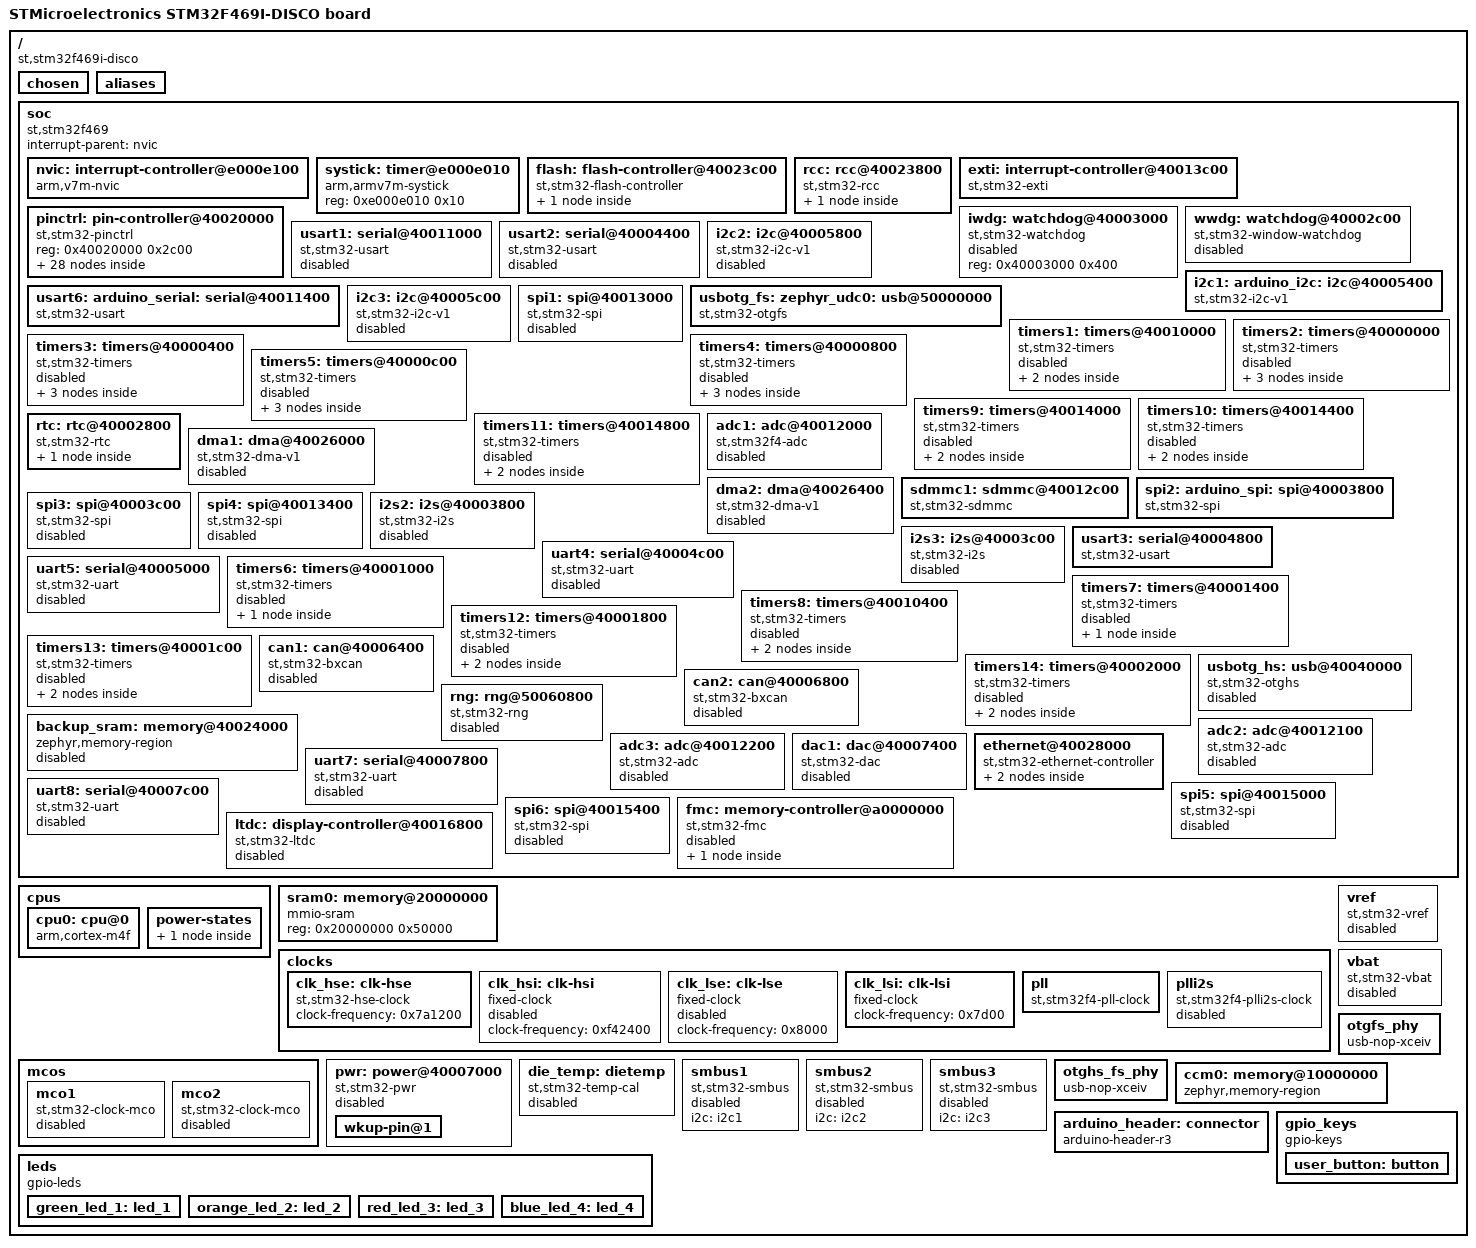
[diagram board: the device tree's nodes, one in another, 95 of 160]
/dts-v1/;

/* node '/' defined in zephyr\dts\common\skeleton.dtsi:9 */
/ {
	#address-cells = < 0x1 >;                            /* in zephyr\dts\common\skeleton.dtsi:10 */
	#size-cells = < 0x1 >;                               /* in zephyr\dts\common\skeleton.dtsi:11 */
	model = "STMicroelectronics STM32F469I-DISCO board"; /* in zephyr\boards\st\stm32f469i_disco\stm32f469i_disco.dts:14 */
	compatible = "st,stm32f469i-disco";                  /* in zephyr\boards\st\stm32f469i_disco\stm32f469i_disco.dts:15 */

	/* node '/chosen' defined in zephyr\dts\common\skeleton.dtsi:12 */
	chosen {
		zephyr,flash-controller = &flash;  /* in zephyr\dts\arm\st\f4\stm32f4.dtsi:26 */
		zephyr,cortex-m-idle-timer = &rtc; /* in zephyr\dts\arm\st\f4\stm32f4.dtsi:27 */
		zephyr,entropy = &rng;             /* in zephyr\dts\arm\st\f4\stm32f405.dtsi:12 */
		zephyr,console = &usart3;          /* in zephyr\boards\st\stm32f469i_disco\stm32f469i_disco.dts:18 */
		zephyr,shell-uart = &usart3;       /* in zephyr\boards\st\stm32f469i_disco\stm32f469i_disco.dts:19 */
		zephyr,sram = &sram0;              /* in zephyr\boards\st\stm32f469i_disco\stm32f469i_disco.dts:20 */
		zephyr,flash = &flash0;            /* in zephyr\boards\st\stm32f469i_disco\stm32f469i_disco.dts:21 */
		zephyr,ccm = &ccm0;                /* in zephyr\boards\st\stm32f469i_disco\stm32f469i_disco.dts:22 */
	};

	/* node '/aliases' defined in zephyr\dts\common\skeleton.dtsi:13 */
	aliases {
		led0 = &green_led_1;  /* in zephyr\boards\st\stm32f469i_disco\stm32f469i_disco.dts:60 */
		led1 = &orange_led_2; /* in zephyr\boards\st\stm32f469i_disco\stm32f469i_disco.dts:61 */
		led2 = &red_led_3;    /* in zephyr\boards\st\stm32f469i_disco\stm32f469i_disco.dts:62 */
		led3 = &blue_led_4;   /* in zephyr\boards\st\stm32f469i_disco\stm32f469i_disco.dts:63 */
		sw0 = &user_button;   /* in zephyr\boards\st\stm32f469i_disco\stm32f469i_disco.dts:64 */
	};

	/* node '/soc' defined in zephyr\dts\arm\armv7-m.dtsi:6 */
	soc {
		#address-cells = < 0x1 >;     /* in zephyr\dts\arm\armv7-m.dtsi:7 */
		#size-cells = < 0x1 >;        /* in zephyr\dts\arm\armv7-m.dtsi:8 */
		interrupt-parent = < &nvic >; /* in zephyr\dts\arm\armv7-m.dtsi:10 */
		ranges;                       /* in zephyr\dts\arm\armv7-m.dtsi:11 */
		compatible = "st,stm32f469",
		             "st,stm32f4",
		             "simple-bus";    /* in zephyr\dts\arm\st\f4\stm32f469.dtsi:11 */

		/* node '/soc/interrupt-controller@e000e100' defined in zephyr\dts\arm\armv7-m.dtsi:13 */
		nvic: interrupt-controller@e000e100 {
			#address-cells = < 0x1 >;            /* in zephyr\dts\arm\armv7-m.dtsi:14 */
			compatible = "arm,v7m-nvic";         /* in zephyr\dts\arm\armv7-m.dtsi:15 */
			reg = < 0xe000e100 0xc00 >;          /* in zephyr\dts\arm\armv7-m.dtsi:16 */
			interrupt-controller;                /* in zephyr\dts\arm\armv7-m.dtsi:17 */
			#interrupt-cells = < 0x2 >;          /* in zephyr\dts\arm\armv7-m.dtsi:18 */
			arm,num-irq-priority-bits = < 0x4 >; /* in zephyr\dts\arm\st\f4\stm32f4.dtsi:664 */
			phandle = < 0x1 >;                   /* in zephyr\dts\arm\armv7-m.dtsi:10 */
		};

		/* node '/soc/timer@e000e010' defined in zephyr\dts\arm\armv7-m.dtsi:21 */
		systick: timer@e000e010 {
			compatible = "arm,armv7m-systick"; /* in zephyr\dts\arm\armv7-m.dtsi:22 */
			reg = < 0xe000e010 0x10 >;         /* in zephyr\dts\arm\armv7-m.dtsi:23 */
		};

		/* node '/soc/flash-controller@40023c00' defined in zephyr\dts\arm\st\f4\stm32f4.dtsi:109 */
		flash: flash-controller@40023c00 {
			compatible = "st,stm32-flash-controller",
			             "st,stm32f4-flash-controller"; /* in zephyr\dts\arm\st\f4\stm32f4.dtsi:110 */
			reg = < 0x40023c00 0x400 >;                 /* in zephyr\dts\arm\st\f4\stm32f4.dtsi:111 */
			interrupts = < 0x4 0x0 >;                   /* in zephyr\dts\arm\st\f4\stm32f4.dtsi:112 */
			#address-cells = < 0x1 >;                   /* in zephyr\dts\arm\st\f4\stm32f4.dtsi:114 */
			#size-cells = < 0x1 >;                      /* in zephyr\dts\arm\st\f4\stm32f4.dtsi:115 */

			/* node '/soc/flash-controller@40023c00/flash@8000000' defined in zephyr\dts\arm\st\f4\stm32f4.dtsi:117 */
			flash0: flash@8000000 {
				compatible = "st,stm32f4-nv-flash",
				             "st,stm32-nv-flash",
				             "soc-nv-flash";        /* in zephyr\dts\arm\st\f4\stm32f4.dtsi:118 */
				write-block-size = < 0x1 >;         /* in zephyr\dts\arm\st\f4\stm32f4.dtsi:121 */
				max-erase-time = < 0xfa0 >;         /* in zephyr\dts\arm\st\f4\stm32f4.dtsi:123 */
				reg = < 0x8000000 0x200000 >;       /* in zephyr\dts\arm\st\f4\stm32f469Xi.dtsi:24 */
			};
		};

		/* node '/soc/rcc@40023800' defined in zephyr\dts\arm\st\f4\stm32f4.dtsi:127 */
		rcc: rcc@40023800 {
			compatible = "st,stm32-rcc";     /* in zephyr\dts\arm\st\f4\stm32f4.dtsi:128 */
			#clock-cells = < 0x2 >;          /* in zephyr\dts\arm\st\f4\stm32f4.dtsi:129 */
			reg = < 0x40023800 0x400 >;      /* in zephyr\dts\arm\st\f4\stm32f4.dtsi:130 */
			clocks = < &pll >;               /* in zephyr\boards\st\stm32f469i_disco\stm32f469i_disco.dts:87 */
			clock-frequency = < 0xa037a00 >; /* in zephyr\boards\st\stm32f469i_disco\stm32f469i_disco.dts:88 */
			ahb-prescaler = < 0x1 >;         /* in zephyr\boards\st\stm32f469i_disco\stm32f469i_disco.dts:89 */
			apb1-prescaler = < 0x4 >;        /* in zephyr\boards\st\stm32f469i_disco\stm32f469i_disco.dts:90 */
			apb2-prescaler = < 0x2 >;        /* in zephyr\boards\st\stm32f469i_disco\stm32f469i_disco.dts:91 */
			phandle = < 0x3 >;               /* in zephyr\dts\arm\st\f4\stm32f4.dtsi:144 */

			/* node '/soc/rcc@40023800/reset-controller' defined in zephyr\dts\arm\st\f4\stm32f4.dtsi:132 */
			rctl: reset-controller {
				compatible = "st,stm32-rcc-rctl"; /* in zephyr\dts\arm\st\f4\stm32f4.dtsi:133 */
				#reset-cells = < 0x1 >;           /* in zephyr\dts\arm\st\f4\stm32f4.dtsi:134 */
				phandle = < 0x4 >;                /* in zephyr\dts\arm\st\f4\stm32f4.dtsi:243 */
			};
		};

		/* node '/soc/interrupt-controller@40013c00' defined in zephyr\dts\arm\st\f4\stm32f4.dtsi:138 */
		exti: interrupt-controller@40013c00 {
			compatible = "st,stm32-exti";  /* in zephyr\dts\arm\st\f4\stm32f4.dtsi:139 */
			interrupt-controller;          /* in zephyr\dts\arm\st\f4\stm32f4.dtsi:140 */
			#interrupt-cells = < 0x1 >;    /* in zephyr\dts\arm\st\f4\stm32f4.dtsi:141 */
			#address-cells = < 0x1 >;      /* in zephyr\dts\arm\st\f4\stm32f4.dtsi:142 */
			reg = < 0x40013c00 0x400 >;    /* in zephyr\dts\arm\st\f4\stm32f4.dtsi:143 */
			clocks = < &rcc 0x44 0x4000 >; /* in zephyr\dts\arm\st\f4\stm32f4.dtsi:144 */
			num-lines = < 0x20 >;          /* in zephyr\dts\arm\st\f4\stm32f4.dtsi:145 */
			interrupts = < 0x6 0x0 >,
			             < 0x7 0x0 >,
			             < 0x8 0x0 >,
			             < 0x9 0x0 >,
			             < 0xa 0x0 >,
			             < 0x17 0x0 >,
			             < 0x28 0x0 >;     /* in zephyr\dts\arm\st\f4\stm32f4.dtsi:146 */
			interrupt-names = "line0",
			                  "line1",
			                  "line2",
			                  "line3",
			                  "line4",
			                  "line5-9",
			                  "line10-15"; /* in zephyr\dts\arm\st\f4\stm32f4.dtsi:148 */
			line-ranges = < 0x0 0x1 >,
			              < 0x1 0x1 >,
			              < 0x2 0x1 >,
			              < 0x3 0x1 >,
			              < 0x4 0x1 >,
			              < 0x5 0x5 >,
			              < 0xa 0x6 >;     /* in zephyr\dts\arm\st\f4\stm32f4.dtsi:150 */
		};

		/* node '/soc/pin-controller@40020000' defined in zephyr\dts\arm\st\f4\stm32f4.dtsi:154 */
		pinctrl: pin-controller@40020000 {
			compatible = "st,stm32-pinctrl"; /* in zephyr\dts\arm\st\f4\stm32f4.dtsi:155 */
			#address-cells = < 0x1 >;        /* in zephyr\dts\arm\st\f4\stm32f4.dtsi:156 */
			#size-cells = < 0x1 >;           /* in zephyr\dts\arm\st\f4\stm32f4.dtsi:157 */
			reg = < 0x40020000 0x2c00 >;     /* in zephyr\dts\arm\st\f4\stm32f427.dtsi:16 */

			/* node '/soc/pin-controller@40020000/gpio@40020000' defined in zephyr\dts\arm\st\f4\stm32f4.dtsi:160 */
			gpioa: gpio@40020000 {
				compatible = "st,stm32-gpio"; /* in zephyr\dts\arm\st\f4\stm32f4.dtsi:161 */
				gpio-controller;              /* in zephyr\dts\arm\st\f4\stm32f4.dtsi:162 */
				#gpio-cells = < 0x2 >;        /* in zephyr\dts\arm\st\f4\stm32f4.dtsi:163 */
				reg = < 0x40020000 0x400 >;   /* in zephyr\dts\arm\st\f4\stm32f4.dtsi:164 */
				clocks = < &rcc 0x30 0x1 >;   /* in zephyr\dts\arm\st\f4\stm32f4.dtsi:165 */
				phandle = < 0x1d >;           /* in zephyr\dts\arm\st\f4\stm32f4.dtsi:603 */
			};

			/* node '/soc/pin-controller@40020000/gpio@40020400' defined in zephyr\dts\arm\st\f4\stm32f4.dtsi:168 */
			gpiob: gpio@40020400 {
				compatible = "st,stm32-gpio"; /* in zephyr\dts\arm\st\f4\stm32f4.dtsi:169 */
				gpio-controller;              /* in zephyr\dts\arm\st\f4\stm32f4.dtsi:170 */
				#gpio-cells = < 0x2 >;        /* in zephyr\dts\arm\st\f4\stm32f4.dtsi:171 */
				reg = < 0x40020400 0x400 >;   /* in zephyr\dts\arm\st\f4\stm32f4.dtsi:172 */
				clocks = < &rcc 0x30 0x2 >;   /* in zephyr\dts\arm\st\f4\stm32f4.dtsi:173 */
				phandle = < 0x22 >;           /* in zephyr\boards\st\stm32f469i_disco\arduino_r3_connector.dtsi:13 */
			};

			/* node '/soc/pin-controller@40020000/gpio@40020800' defined in zephyr\dts\arm\st\f4\stm32f4.dtsi:176 */
			gpioc: gpio@40020800 {
				compatible = "st,stm32-gpio"; /* in zephyr\dts\arm\st\f4\stm32f4.dtsi:177 */
				gpio-controller;              /* in zephyr\dts\arm\st\f4\stm32f4.dtsi:178 */
				#gpio-cells = < 0x2 >;        /* in zephyr\dts\arm\st\f4\stm32f4.dtsi:179 */
				reg = < 0x40020800 0x400 >;   /* in zephyr\dts\arm\st\f4\stm32f4.dtsi:180 */
				clocks = < &rcc 0x30 0x4 >;   /* in zephyr\dts\arm\st\f4\stm32f4.dtsi:181 */
				phandle = < 0x23 >;           /* in zephyr\boards\st\stm32f469i_disco\arduino_r3_connector.dtsi:13 */
			};

			/* node '/soc/pin-controller@40020000/gpio@40020c00' defined in zephyr\dts\arm\st\f4\stm32f4.dtsi:184 */
			gpiod: gpio@40020c00 {
				compatible = "st,stm32-gpio"; /* in zephyr\dts\arm\st\f4\stm32f4.dtsi:185 */
				gpio-controller;              /* in zephyr\dts\arm\st\f4\stm32f4.dtsi:186 */
				#gpio-cells = < 0x2 >;        /* in zephyr\dts\arm\st\f4\stm32f4.dtsi:187 */
				reg = < 0x40020c00 0x400 >;   /* in zephyr\dts\arm\st\f4\stm32f4.dtsi:188 */
				clocks = < &rcc 0x30 0x8 >;   /* in zephyr\dts\arm\st\f4\stm32f4.dtsi:189 */
				phandle = < 0x24 >;           /* in zephyr\boards\st\stm32f469i_disco\arduino_r3_connector.dtsi:13 */
			};

			/* node '/soc/pin-controller@40020000/gpio@40021000' defined in zephyr\dts\arm\st\f4\stm32f4.dtsi:192 */
			gpioe: gpio@40021000 {
				compatible = "st,stm32-gpio"; /* in zephyr\dts\arm\st\f4\stm32f4.dtsi:193 */
				gpio-controller;              /* in zephyr\dts\arm\st\f4\stm32f4.dtsi:194 */
				#gpio-cells = < 0x2 >;        /* in zephyr\dts\arm\st\f4\stm32f4.dtsi:195 */
				reg = < 0x40021000 0x400 >;   /* in zephyr\dts\arm\st\f4\stm32f4.dtsi:196 */
				clocks = < &rcc 0x30 0x10 >;  /* in zephyr\dts\arm\st\f4\stm32f4.dtsi:197 */
			};

			/* node '/soc/pin-controller@40020000/gpio@40021400' defined in zephyr\dts\arm\st\f4\stm32f4.dtsi:200 */
			gpiof: gpio@40021400 {
				compatible = "st,stm32-gpio"; /* in zephyr\dts\arm\st\f4\stm32f405.dtsi:22 */
				gpio-controller;              /* in zephyr\dts\arm\st\f4\stm32f405.dtsi:23 */
				#gpio-cells = < 0x2 >;        /* in zephyr\dts\arm\st\f4\stm32f405.dtsi:24 */
				reg = < 0x40021400 0x400 >;   /* in zephyr\dts\arm\st\f4\stm32f405.dtsi:25 */
				clocks = < &rcc 0x30 0x20 >;  /* in zephyr\dts\arm\st\f4\stm32f405.dtsi:26 */
			};

			/* node '/soc/pin-controller@40020000/gpio@40021800' defined in zephyr\dts\arm\st\f4\stm32f4.dtsi:208 */
			gpiog: gpio@40021800 {
				compatible = "st,stm32-gpio"; /* in zephyr\dts\arm\st\f4\stm32f405.dtsi:30 */
				gpio-controller;              /* in zephyr\dts\arm\st\f4\stm32f405.dtsi:31 */
				#gpio-cells = < 0x2 >;        /* in zephyr\dts\arm\st\f4\stm32f405.dtsi:32 */
				reg = < 0x40021800 0x400 >;   /* in zephyr\dts\arm\st\f4\stm32f405.dtsi:33 */
				clocks = < &rcc 0x30 0x40 >;  /* in zephyr\dts\arm\st\f4\stm32f405.dtsi:34 */
				phandle = < 0x12 >;           /* in zephyr\boards\st\stm32f469i_disco\stm32f469i_disco.dts:144 */
			};

			/* node '/soc/pin-controller@40020000/gpio@40021c00' defined in zephyr\dts\arm\st\f4\stm32f4.dtsi:216 */
			gpioh: gpio@40021c00 {
				compatible = "st,stm32-gpio"; /* in zephyr\dts\arm\st\f4\stm32f4.dtsi:217 */
				gpio-controller;              /* in zephyr\dts\arm\st\f4\stm32f4.dtsi:218 */
				#gpio-cells = < 0x2 >;        /* in zephyr\dts\arm\st\f4\stm32f4.dtsi:219 */
				reg = < 0x40021c00 0x400 >;   /* in zephyr\dts\arm\st\f4\stm32f4.dtsi:220 */
				clocks = < &rcc 0x30 0x80 >;  /* in zephyr\dts\arm\st\f4\stm32f4.dtsi:221 */
				phandle = < 0x16 >;           /* in zephyr\boards\st\stm32f469i_disco\stm32f469i_disco.dts:117 */
			};

			/* node '/soc/pin-controller@40020000/gpio@40022000' defined in zephyr\dts\arm\st\f4\stm32f405.dtsi:37 */
			gpioi: gpio@40022000 {
				compatible = "st,stm32-gpio"; /* in zephyr\dts\arm\st\f4\stm32f405.dtsi:38 */
				gpio-controller;              /* in zephyr\dts\arm\st\f4\stm32f405.dtsi:39 */
				#gpio-cells = < 0x2 >;        /* in zephyr\dts\arm\st\f4\stm32f405.dtsi:40 */
				reg = < 0x40022000 0x400 >;   /* in zephyr\dts\arm\st\f4\stm32f405.dtsi:41 */
				clocks = < &rcc 0x30 0x100 >; /* in zephyr\dts\arm\st\f4\stm32f405.dtsi:42 */
			};

			/* node '/soc/pin-controller@40020000/gpio@40022400' defined in zephyr\dts\arm\st\f4\stm32f427.dtsi:18 */
			gpioj: gpio@40022400 {
				compatible = "st,stm32-gpio"; /* in zephyr\dts\arm\st\f4\stm32f427.dtsi:19 */
				gpio-controller;              /* in zephyr\dts\arm\st\f4\stm32f427.dtsi:20 */
				#gpio-cells = < 0x2 >;        /* in zephyr\dts\arm\st\f4\stm32f427.dtsi:21 */
				reg = < 0x40022400 0x400 >;   /* in zephyr\dts\arm\st\f4\stm32f427.dtsi:22 */
				clocks = < &rcc 0x30 0x200 >; /* in zephyr\dts\arm\st\f4\stm32f427.dtsi:23 */
			};

			/* node '/soc/pin-controller@40020000/gpio@40022800' defined in zephyr\dts\arm\st\f4\stm32f427.dtsi:26 */
			gpiok: gpio@40022800 {
				compatible = "st,stm32-gpio"; /* in zephyr\dts\arm\st\f4\stm32f427.dtsi:27 */
				gpio-controller;              /* in zephyr\dts\arm\st\f4\stm32f427.dtsi:28 */
				#gpio-cells = < 0x2 >;        /* in zephyr\dts\arm\st\f4\stm32f427.dtsi:29 */
				reg = < 0x40022800 0x400 >;   /* in zephyr\dts\arm\st\f4\stm32f427.dtsi:30 */
				clocks = < &rcc 0x30 0x400 >; /* in zephyr\dts\arm\st\f4\stm32f427.dtsi:31 */
				phandle = < 0x25 >;           /* in zephyr\boards\st\stm32f469i_disco\stm32f469i_disco.dts:44 */
			};

			/* node '/soc/pin-controller@40020000/i2c1_scl_pb8' defined in modules\hal\stm32\dts\st\f4\stm32f469nihx-pinctrl.dtsi:1856 */
			i2c1_scl_pb8: i2c1_scl_pb8 {
				pinmux = < 0x304 >; /* in modules\hal\stm32\dts\st\f4\stm32f469nihx-pinctrl.dtsi:1857 */
				bias-pull-up;       /* in modules\hal\stm32\dts\st\f4\stm32f469nihx-pinctrl.dtsi:1858 */
				drive-open-drain;   /* in modules\hal\stm32\dts\st\f4\stm32f469nihx-pinctrl.dtsi:1859 */
				phandle = < 0x7 >;  /* in zephyr\boards\st\stm32f469i_disco\stm32f469i_disco.dts:109 */
			};

			/* node '/soc/pin-controller@40020000/i2c1_sda_pb9' defined in modules\hal\stm32\dts\st\f4\stm32f469nihx-pinctrl.dtsi:1900 */
			i2c1_sda_pb9: i2c1_sda_pb9 {
				pinmux = < 0x324 >; /* in modules\hal\stm32\dts\st\f4\stm32f469nihx-pinctrl.dtsi:1901 */
				bias-pull-up;       /* in modules\hal\stm32\dts\st\f4\stm32f469nihx-pinctrl.dtsi:1902 */
				drive-open-drain;   /* in modules\hal\stm32\dts\st\f4\stm32f469nihx-pinctrl.dtsi:1903 */
				phandle = < 0x8 >;  /* in zephyr\boards\st\stm32f469i_disco\stm32f469i_disco.dts:109 */
			};

			/* node '/soc/pin-controller@40020000/sdio_d0_pc8' defined in modules\hal\stm32\dts\st\f4\stm32f469nihx-pinctrl.dtsi:2663 */
			sdio_d0_pc8: sdio_d0_pc8 {
				pinmux = < 0x50c >;            /* in modules\hal\stm32\dts\st\f4\stm32f469nihx-pinctrl.dtsi:2664 */
				bias-pull-up;                  /* in modules\hal\stm32\dts\st\f4\stm32f469nihx-pinctrl.dtsi:2665 */
				slew-rate = "very-high-speed"; /* in modules\hal\stm32\dts\st\f4\stm32f469nihx-pinctrl.dtsi:2666 */
				phandle = < 0xc >;             /* in zephyr\boards\st\stm32f469i_disco\stm32f469i_disco.dts:137 */
			};

			/* node '/soc/pin-controller@40020000/sdio_d1_pc9' defined in modules\hal\stm32\dts\st\f4\stm32f469nihx-pinctrl.dtsi:2669 */
			sdio_d1_pc9: sdio_d1_pc9 {
				pinmux = < 0x52c >;            /* in modules\hal\stm32\dts\st\f4\stm32f469nihx-pinctrl.dtsi:2670 */
				bias-pull-up;                  /* in modules\hal\stm32\dts\st\f4\stm32f469nihx-pinctrl.dtsi:2671 */
				slew-rate = "very-high-speed"; /* in modules\hal\stm32\dts\st\f4\stm32f469nihx-pinctrl.dtsi:2672 */
				phandle = < 0xd >;             /* in zephyr\boards\st\stm32f469i_disco\stm32f469i_disco.dts:137 */
			};

			/* node '/soc/pin-controller@40020000/sdio_d2_pc10' defined in modules\hal\stm32\dts\st\f4\stm32f469nihx-pinctrl.dtsi:2675 */
			sdio_d2_pc10: sdio_d2_pc10 {
				pinmux = < 0x54c >;            /* in modules\hal\stm32\dts\st\f4\stm32f469nihx-pinctrl.dtsi:2676 */
				bias-pull-up;                  /* in modules\hal\stm32\dts\st\f4\stm32f469nihx-pinctrl.dtsi:2677 */
				slew-rate = "very-high-speed"; /* in modules\hal\stm32\dts\st\f4\stm32f469nihx-pinctrl.dtsi:2678 */
				phandle = < 0xe >;             /* in zephyr\boards\st\stm32f469i_disco\stm32f469i_disco.dts:137 */
			};

			/* node '/soc/pin-controller@40020000/sdio_d3_pc11' defined in modules\hal\stm32\dts\st\f4\stm32f469nihx-pinctrl.dtsi:2681 */
			sdio_d3_pc11: sdio_d3_pc11 {
				pinmux = < 0x56c >;            /* in modules\hal\stm32\dts\st\f4\stm32f469nihx-pinctrl.dtsi:2682 */
				bias-pull-up;                  /* in modules\hal\stm32\dts\st\f4\stm32f469nihx-pinctrl.dtsi:2683 */
				slew-rate = "very-high-speed"; /* in modules\hal\stm32\dts\st\f4\stm32f469nihx-pinctrl.dtsi:2684 */
				phandle = < 0xf >;             /* in zephyr\boards\st\stm32f469i_disco\stm32f469i_disco.dts:137 */
			};

			/* node '/soc/pin-controller@40020000/sdio_ck_pc12' defined in modules\hal\stm32\dts\st\f4\stm32f469nihx-pinctrl.dtsi:2687 */
			sdio_ck_pc12: sdio_ck_pc12 {
				pinmux = < 0x58c >;            /* in modules\hal\stm32\dts\st\f4\stm32f469nihx-pinctrl.dtsi:2688 */
				bias-pull-up;                  /* in modules\hal\stm32\dts\st\f4\stm32f469nihx-pinctrl.dtsi:2689 */
				slew-rate = "very-high-speed"; /* in modules\hal\stm32\dts\st\f4\stm32f469nihx-pinctrl.dtsi:2690 */
				phandle = < 0x10 >;            /* in zephyr\boards\st\stm32f469i_disco\stm32f469i_disco.dts:137 */
			};

			/* node '/soc/pin-controller@40020000/sdio_cmd_pd2' defined in modules\hal\stm32\dts\st\f4\stm32f469nihx-pinctrl.dtsi:2693 */
			sdio_cmd_pd2: sdio_cmd_pd2 {
				pinmux = < 0x64c >;            /* in modules\hal\stm32\dts\st\f4\stm32f469nihx-pinctrl.dtsi:2694 */
				bias-pull-up;                  /* in modules\hal\stm32\dts\st\f4\stm32f469nihx-pinctrl.dtsi:2695 */
				slew-rate = "very-high-speed"; /* in modules\hal\stm32\dts\st\f4\stm32f469nihx-pinctrl.dtsi:2696 */
				phandle = < 0x11 >;            /* in zephyr\boards\st\stm32f469i_disco\stm32f469i_disco.dts:137 */
			};

			/* node '/soc/pin-controller@40020000/spi2_miso_pb14' defined in modules\hal\stm32\dts\st\f4\stm32f469nihx-pinctrl.dtsi:2711 */
			spi2_miso_pb14: spi2_miso_pb14 {
				pinmux = < 0x3c5 >; /* in modules\hal\stm32\dts\st\f4\stm32f469nihx-pinctrl.dtsi:2712 */
				bias-pull-down;     /* in modules\hal\stm32\dts\st\f4\stm32f469nihx-pinctrl.dtsi:2713 */
				phandle = < 0x14 >; /* in zephyr\boards\st\stm32f469i_disco\stm32f469i_disco.dts:115 */
			};

			/* node '/soc/pin-controller@40020000/spi2_mosi_pb15' defined in modules\hal\stm32\dts\st\f4\stm32f469nihx-pinctrl.dtsi:2773 */
			spi2_mosi_pb15: spi2_mosi_pb15 {
				pinmux = < 0x3e5 >; /* in modules\hal\stm32\dts\st\f4\stm32f469nihx-pinctrl.dtsi:2774 */
				bias-pull-down;     /* in modules\hal\stm32\dts\st\f4\stm32f469nihx-pinctrl.dtsi:2775 */
				phandle = < 0x15 >; /* in zephyr\boards\st\stm32f469i_disco\stm32f469i_disco.dts:115 */
			};

			/* node '/soc/pin-controller@40020000/spi2_sck_pd3' defined in modules\hal\stm32\dts\st\f4\stm32f469nihx-pinctrl.dtsi:2927 */
			spi2_sck_pd3: spi2_sck_pd3 {
				pinmux = < 0x665 >;            /* in modules\hal\stm32\dts\st\f4\stm32f469nihx-pinctrl.dtsi:2928 */
				bias-pull-down;                /* in modules\hal\stm32\dts\st\f4\stm32f469nihx-pinctrl.dtsi:2929 */
				slew-rate = "very-high-speed"; /* in modules\hal\stm32\dts\st\f4\stm32f469nihx-pinctrl.dtsi:2930 */
				phandle = < 0x13 >;            /* in zephyr\boards\st\stm32f469i_disco\stm32f469i_disco.dts:115 */
			};

			/* node '/soc/pin-controller@40020000/usart3_rx_pb11' defined in modules\hal\stm32\dts\st\f4\stm32f469nihx-pinctrl.dtsi:3437 */
			usart3_rx_pb11: usart3_rx_pb11 {
				pinmux = < 0x367 >; /* in modules\hal\stm32\dts\st\f4\stm32f469nihx-pinctrl.dtsi:3438 */
				phandle = < 0x19 >; /* in zephyr\boards\st\stm32f469i_disco\stm32f469i_disco.dts:95 */
			};

			/* node '/soc/pin-controller@40020000/usart6_rx_pg9' defined in modules\hal\stm32\dts\st\f4\stm32f469nihx-pinctrl.dtsi:3465 */
			usart6_rx_pg9: usart6_rx_pg9 {
				pinmux = < 0xd28 >; /* in modules\hal\stm32\dts\st\f4\stm32f469nihx-pinctrl.dtsi:3466 */
				phandle = < 0x6 >;  /* in zephyr\boards\st\stm32f469i_disco\stm32f469i_disco.dts:102 */
			};

			/* node '/soc/pin-controller@40020000/usart3_tx_pb10' defined in modules\hal\stm32\dts\st\f4\stm32f469nihx-pinctrl.dtsi:3503 */
			usart3_tx_pb10: usart3_tx_pb10 {
				pinmux = < 0x347 >; /* in modules\hal\stm32\dts\st\f4\stm32f469nihx-pinctrl.dtsi:3504 */
				bias-pull-up;       /* in modules\hal\stm32\dts\st\f4\stm32f469nihx-pinctrl.dtsi:3505 */
				phandle = < 0x18 >; /* in zephyr\boards\st\stm32f469i_disco\stm32f469i_disco.dts:95 */
			};

			/* node '/soc/pin-controller@40020000/usart6_tx_pg14' defined in modules\hal\stm32\dts\st\f4\stm32f469nihx-pinctrl.dtsi:3538 */
			usart6_tx_pg14: usart6_tx_pg14 {
				pinmux = < 0xdc8 >; /* in modules\hal\stm32\dts\st\f4\stm32f469nihx-pinctrl.dtsi:3539 */
				bias-pull-up;       /* in modules\hal\stm32\dts\st\f4\stm32f469nihx-pinctrl.dtsi:3540 */
				phandle = < 0x5 >;  /* in zephyr\boards\st\stm32f469i_disco\stm32f469i_disco.dts:102 */
			};

			/* node '/soc/pin-controller@40020000/usb_otg_fs_dm_pa11' defined in modules\hal\stm32\dts\st\f4\stm32f469nihx-pinctrl.dtsi:3572 */
			usb_otg_fs_dm_pa11: usb_otg_fs_dm_pa11 {
				pinmux = < 0x16a >; /* in modules\hal\stm32\dts\st\f4\stm32f469nihx-pinctrl.dtsi:3573 */
				phandle = < 0xa >;  /* in zephyr\boards\st\stm32f469i_disco\stm32f469i_disco.dts:122 */
			};

			/* node '/soc/pin-controller@40020000/usb_otg_fs_dp_pa12' defined in modules\hal\stm32\dts\st\f4\stm32f469nihx-pinctrl.dtsi:3576 */
			usb_otg_fs_dp_pa12: usb_otg_fs_dp_pa12 {
				pinmux = < 0x18a >; /* in modules\hal\stm32\dts\st\f4\stm32f469nihx-pinctrl.dtsi:3577 */
				phandle = < 0xb >;  /* in zephyr\boards\st\stm32f469i_disco\stm32f469i_disco.dts:122 */
			};
		};

		/* node '/soc/watchdog@40003000' defined in zephyr\dts\arm\st\f4\stm32f4.dtsi:225 */
		iwdg: watchdog@40003000 {
			compatible = "st,stm32-watchdog"; /* in zephyr\dts\arm\st\f4\stm32f4.dtsi:226 */
			reg = < 0x40003000 0x400 >;       /* in zephyr\dts\arm\st\f4\stm32f4.dtsi:227 */
			status = "disabled";              /* in zephyr\dts\arm\st\f4\stm32f4.dtsi:228 */
		};

		/* node '/soc/watchdog@40002c00' defined in zephyr\dts\arm\st\f4\stm32f4.dtsi:231 */
		wwdg: watchdog@40002c00 {
			compatible = "st,stm32-window-watchdog"; /* in zephyr\dts\arm\st\f4\stm32f4.dtsi:232 */
			reg = < 0x40002c00 0x400 >;              /* in zephyr\dts\arm\st\f4\stm32f4.dtsi:233 */
			clocks = < &rcc 0x40 0x800 >;            /* in zephyr\dts\arm\st\f4\stm32f4.dtsi:234 */
			interrupts = < 0x0 0x7 >;                /* in zephyr\dts\arm\st\f4\stm32f4.dtsi:235 */
			status = "disabled";                     /* in zephyr\dts\arm\st\f4\stm32f4.dtsi:236 */
		};

		/* node '/soc/serial@40011000' defined in zephyr\dts\arm\st\f4\stm32f4.dtsi:239 */
		usart1: serial@40011000 {
			compatible = "st,stm32-usart",
			             "st,stm32-uart";  /* in zephyr\dts\arm\st\f4\stm32f4.dtsi:240 */
			reg = < 0x40011000 0x400 >;    /* in zephyr\dts\arm\st\f4\stm32f4.dtsi:241 */
			clocks = < &rcc 0x44 0x10 >;   /* in zephyr\dts\arm\st\f4\stm32f4.dtsi:242 */
			resets = < &rctl 0x484 >;      /* in zephyr\dts\arm\st\f4\stm32f4.dtsi:243 */
			interrupts = < 0x25 0x0 >;     /* in zephyr\dts\arm\st\f4\stm32f4.dtsi:244 */
			status = "disabled";           /* in zephyr\dts\arm\st\f4\stm32f4.dtsi:245 */
		};

		/* node '/soc/serial@40004400' defined in zephyr\dts\arm\st\f4\stm32f4.dtsi:248 */
		usart2: serial@40004400 {
			compatible = "st,stm32-usart",
			             "st,stm32-uart";   /* in zephyr\dts\arm\st\f4\stm32f4.dtsi:249 */
			reg = < 0x40004400 0x400 >;     /* in zephyr\dts\arm\st\f4\stm32f4.dtsi:250 */
			clocks = < &rcc 0x40 0x20000 >; /* in zephyr\dts\arm\st\f4\stm32f4.dtsi:251 */
			resets = < &rctl 0x411 >;       /* in zephyr\dts\arm\st\f4\stm32f4.dtsi:252 */
			interrupts = < 0x26 0x0 >;      /* in zephyr\dts\arm\st\f4\stm32f4.dtsi:253 */
			status = "disabled";            /* in zephyr\dts\arm\st\f4\stm32f4.dtsi:254 */
		};

		/* node '/soc/serial@40011400' defined in zephyr\dts\arm\st\f4\stm32f4.dtsi:257 */
		usart6: arduino_serial: serial@40011400 {
			compatible = "st,stm32-usart",
			             "st,stm32-uart";                   /* in zephyr\dts\arm\st\f4\stm32f4.dtsi:258 */
			reg = < 0x40011400 0x400 >;                     /* in zephyr\dts\arm\st\f4\stm32f4.dtsi:259 */
			clocks = < &rcc 0x44 0x20 >;                    /* in zephyr\dts\arm\st\f4\stm32f4.dtsi:260 */
			resets = < &rctl 0x485 >;                       /* in zephyr\dts\arm\st\f4\stm32f4.dtsi:261 */
			interrupts = < 0x47 0x0 >;                      /* in zephyr\dts\arm\st\f4\stm32f4.dtsi:262 */
			pinctrl-0 = < &usart6_tx_pg14 &usart6_rx_pg9 >; /* in zephyr\boards\st\stm32f469i_disco\stm32f469i_disco.dts:102 */
			pinctrl-names = "default";                      /* in zephyr\boards\st\stm32f469i_disco\stm32f469i_disco.dts:103 */
			current-speed = < 0x1c200 >;                    /* in zephyr\boards\st\stm32f469i_disco\stm32f469i_disco.dts:104 */
			status = "okay";                                /* in zephyr\boards\st\stm32f469i_disco\stm32f469i_disco.dts:105 */
		};

		/* node '/soc/i2c@40005400' defined in zephyr\dts\arm\st\f4\stm32f4.dtsi:266 */
		i2c1: arduino_i2c: i2c@40005400 {
			compatible = "st,stm32-i2c-v1";              /* in zephyr\dts\arm\st\f4\stm32f4.dtsi:267 */
			clock-frequency = < 0x186a0 >;               /* in zephyr\dts\arm\st\f4\stm32f4.dtsi:268 */
			#address-cells = < 0x1 >;                    /* in zephyr\dts\arm\st\f4\stm32f4.dtsi:269 */
			#size-cells = < 0x0 >;                       /* in zephyr\dts\arm\st\f4\stm32f4.dtsi:270 */
			reg = < 0x40005400 0x400 >;                  /* in zephyr\dts\arm\st\f4\stm32f4.dtsi:271 */
			clocks = < &rcc 0x40 0x200000 >;             /* in zephyr\dts\arm\st\f4\stm32f4.dtsi:272 */
			interrupts = < 0x1f 0x0 >,
			             < 0x20 0x0 >;                   /* in zephyr\dts\arm\st\f4\stm32f4.dtsi:273 */
			interrupt-names = "event",
			                  "error";                   /* in zephyr\dts\arm\st\f4\stm32f4.dtsi:274 */
			pinctrl-0 = < &i2c1_scl_pb8 &i2c1_sda_pb9 >; /* in zephyr\boards\st\stm32f469i_disco\stm32f469i_disco.dts:109 */
			pinctrl-names = "default";                   /* in zephyr\boards\st\stm32f469i_disco\stm32f469i_disco.dts:110 */
			status = "okay";                             /* in zephyr\boards\st\stm32f469i_disco\stm32f469i_disco.dts:111 */
			phandle = < 0x1f >;                          /* in zephyr\dts\arm\st\f4\stm32f4.dtsi:642 */
		};

		/* node '/soc/i2c@40005800' defined in zephyr\dts\arm\st\f4\stm32f4.dtsi:278 */
		i2c2: i2c@40005800 {
			compatible = "st,stm32-i2c-v1";  /* in zephyr\dts\arm\st\f4\stm32f4.dtsi:279 */
			clock-frequency = < 0x186a0 >;   /* in zephyr\dts\arm\st\f4\stm32f4.dtsi:280 */
			#address-cells = < 0x1 >;        /* in zephyr\dts\arm\st\f4\stm32f4.dtsi:281 */
			#size-cells = < 0x0 >;           /* in zephyr\dts\arm\st\f4\stm32f4.dtsi:282 */
			reg = < 0x40005800 0x400 >;      /* in zephyr\dts\arm\st\f4\stm32f4.dtsi:283 */
			clocks = < &rcc 0x40 0x400000 >; /* in zephyr\dts\arm\st\f4\stm32f4.dtsi:284 */
			interrupts = < 0x21 0x0 >,
			             < 0x22 0x0 >;       /* in zephyr\dts\arm\st\f4\stm32f4.dtsi:285 */
			interrupt-names = "event",
			                  "error";       /* in zephyr\dts\arm\st\f4\stm32f4.dtsi:286 */
			status = "disabled";             /* in zephyr\dts\arm\st\f4\stm32f4.dtsi:287 */
			phandle = < 0x20 >;              /* in zephyr\dts\arm\st\f4\stm32f4.dtsi:650 */
		};

		/* node '/soc/i2c@40005c00' defined in zephyr\dts\arm\st\f4\stm32f4.dtsi:290 */
		i2c3: i2c@40005c00 {
			compatible = "st,stm32-i2c-v1";  /* in zephyr\dts\arm\st\f4\stm32f4.dtsi:291 */
			clock-frequency = < 0x186a0 >;   /* in zephyr\dts\arm\st\f4\stm32f4.dtsi:292 */
			#address-cells = < 0x1 >;        /* in zephyr\dts\arm\st\f4\stm32f4.dtsi:293 */
			#size-cells = < 0x0 >;           /* in zephyr\dts\arm\st\f4\stm32f4.dtsi:294 */
			reg = < 0x40005c00 0x400 >;      /* in zephyr\dts\arm\st\f4\stm32f4.dtsi:295 */
			clocks = < &rcc 0x40 0x800000 >; /* in zephyr\dts\arm\st\f4\stm32f4.dtsi:296 */
			interrupts = < 0x48 0x0 >,
			             < 0x49 0x0 >;       /* in zephyr\dts\arm\st\f4\stm32f4.dtsi:297 */
			interrupt-names = "event",
			                  "error";       /* in zephyr\dts\arm\st\f4\stm32f4.dtsi:298 */
			status = "disabled";             /* in zephyr\dts\arm\st\f4\stm32f4.dtsi:299 */
			phandle = < 0x21 >;              /* in zephyr\dts\arm\st\f4\stm32f4.dtsi:658 */
		};

		/* node '/soc/spi@40013000' defined in zephyr\dts\arm\st\f4\stm32f4.dtsi:302 */
		spi1: spi@40013000 {
			compatible = "st,stm32-spi";   /* in zephyr\dts\arm\st\f4\stm32f4.dtsi:303 */
			#address-cells = < 0x1 >;      /* in zephyr\dts\arm\st\f4\stm32f4.dtsi:304 */
			#size-cells = < 0x0 >;         /* in zephyr\dts\arm\st\f4\stm32f4.dtsi:305 */
			reg = < 0x40013000 0x400 >;    /* in zephyr\dts\arm\st\f4\stm32f4.dtsi:306 */
			clocks = < &rcc 0x44 0x1000 >; /* in zephyr\dts\arm\st\f4\stm32f4.dtsi:307 */
			interrupts = < 0x23 0x5 >;     /* in zephyr\dts\arm\st\f4\stm32f4.dtsi:308 */
			status = "disabled";           /* in zephyr\dts\arm\st\f4\stm32f4.dtsi:309 */
		};

		/* node '/soc/usb@50000000' defined in zephyr\dts\arm\st\f4\stm32f4.dtsi:312 */
		usbotg_fs: zephyr_udc0: usb@50000000 {
			compatible = "st,stm32-otgfs";                           /* in zephyr\dts\arm\st\f4\stm32f4.dtsi:313 */
			reg = < 0x50000000 0x40000 >;                            /* in zephyr\dts\arm\st\f4\stm32f4.dtsi:314 */
			interrupts = < 0x43 0x0 >;                               /* in zephyr\dts\arm\st\f4\stm32f4.dtsi:315 */
			interrupt-names = "otgfs";                               /* in zephyr\dts\arm\st\f4\stm32f4.dtsi:316 */
			ram-size = < 0x500 >;                                    /* in zephyr\dts\arm\st\f4\stm32f4.dtsi:318 */
			maximum-speed = "full-speed";                            /* in zephyr\dts\arm\st\f4\stm32f4.dtsi:319 */
			phys = < &otgfs_phy >;                                   /* in zephyr\dts\arm\st\f4\stm32f4.dtsi:320 */
			num-bidir-endpoints = < 0x6 >;                           /* in zephyr\dts\arm\st\f4\stm32f469.dtsi:19 */
			clocks = < &rcc 0x34 0x80 >,
			         < &rcc 0x7 0x5b008c >;                          /* in zephyr\dts\arm\st\f4\stm32f469.dtsi:20 */
			pinctrl-0 = < &usb_otg_fs_dm_pa11 &usb_otg_fs_dp_pa12 >; /* in zephyr\boards\st\stm32f469i_disco\stm32f469i_disco.dts:122 */
			pinctrl-names = "default";                               /* in zephyr\boards\st\stm32f469i_disco\stm32f469i_disco.dts:123 */
			status = "okay";                                         /* in zephyr\boards\st\stm32f469i_disco\stm32f469i_disco.dts:124 */
		};

		/* node '/soc/timers@40010000' defined in zephyr\dts\arm\st\f4\stm32f4.dtsi:326 */
		timers1: timers@40010000 {
			compatible = "st,stm32-timers"; /* in zephyr\dts\arm\st\f4\stm32f4.dtsi:327 */
			reg = < 0x40010000 0x400 >;     /* in zephyr\dts\arm\st\f4\stm32f4.dtsi:328 */
			clocks = < &rcc 0x44 0x1 >;     /* in zephyr\dts\arm\st\f4\stm32f4.dtsi:329 */
			resets = < &rctl 0x480 >;       /* in zephyr\dts\arm\st\f4\stm32f4.dtsi:330 */
			interrupts = < 0x18 0x0 >,
			             < 0x19 0x0 >,
			             < 0x1a 0x0 >,
			             < 0x1b 0x0 >;      /* in zephyr\dts\arm\st\f4\stm32f4.dtsi:331 */
			interrupt-names = "brk",
			                  "up",
			                  "trgcom",
			                  "cc";         /* in zephyr\dts\arm\st\f4\stm32f4.dtsi:332 */
			st,prescaler = < 0x0 >;         /* in zephyr\dts\arm\st\f4\stm32f4.dtsi:333 */
			status = "disabled";            /* in zephyr\dts\arm\st\f4\stm32f4.dtsi:334 */

			/* node '/soc/timers@40010000/pwm' defined in zephyr\dts\arm\st\f4\stm32f4.dtsi:336 */
			pwm {
				compatible = "st,stm32-pwm"; /* in zephyr\dts\arm\st\f4\stm32f4.dtsi:337 */
				status = "disabled";         /* in zephyr\dts\arm\st\f4\stm32f4.dtsi:338 */
				#pwm-cells = < 0x3 >;        /* in zephyr\dts\arm\st\f4\stm32f4.dtsi:339 */
			};

			/* node '/soc/timers@40010000/qdec' defined in zephyr\dts\arm\st\f4\stm32f4.dtsi:342 */
			qdec {
				compatible = "st,stm32-qdec";    /* in zephyr\dts\arm\st\f4\stm32f4.dtsi:343 */
				status = "disabled";             /* in zephyr\dts\arm\st\f4\stm32f4.dtsi:344 */
				st,input-filter-level = < 0x0 >; /* in zephyr\dts\arm\st\f4\stm32f4.dtsi:345 */
			};
		};

		/* node '/soc/timers@40000000' defined in zephyr\dts\arm\st\f4\stm32f4.dtsi:349 */
		timers2: timers@40000000 {
			compatible = "st,stm32-timers"; /* in zephyr\dts\arm\st\f4\stm32f4.dtsi:350 */
			reg = < 0x40000000 0x400 >;     /* in zephyr\dts\arm\st\f4\stm32f4.dtsi:351 */
			clocks = < &rcc 0x40 0x1 >;     /* in zephyr\dts\arm\st\f4\stm32f4.dtsi:352 */
			resets = < &rctl 0x400 >;       /* in zephyr\dts\arm\st\f4\stm32f4.dtsi:353 */
			interrupts = < 0x1c 0x0 >;      /* in zephyr\dts\arm\st\f4\stm32f4.dtsi:354 */
			interrupt-names = "global";     /* in zephyr\dts\arm\st\f4\stm32f4.dtsi:355 */
			st,prescaler = < 0x0 >;         /* in zephyr\dts\arm\st\f4\stm32f4.dtsi:356 */
			status = "disabled";            /* in zephyr\dts\arm\st\f4\stm32f4.dtsi:357 */

			/* node '/soc/timers@40000000/pwm' defined in zephyr\dts\arm\st\f4\stm32f4.dtsi:359 */
			pwm {
				compatible = "st,stm32-pwm"; /* in zephyr\dts\arm\st\f4\stm32f4.dtsi:360 */
				status = "disabled";         /* in zephyr\dts\arm\st\f4\stm32f4.dtsi:361 */
				#pwm-cells = < 0x3 >;        /* in zephyr\dts\arm\st\f4\stm32f4.dtsi:362 */
			};

			/* node '/soc/timers@40000000/counter' defined in zephyr\dts\arm\st\f4\stm32f4.dtsi:365 */
			counter {
				compatible = "st,stm32-counter"; /* in zephyr\dts\arm\st\f4\stm32f4.dtsi:366 */
				status = "disabled";             /* in zephyr\dts\arm\st\f4\stm32f4.dtsi:367 */
			};

			/* node '/soc/timers@40000000/qdec' defined in zephyr\dts\arm\st\f4\stm32f4.dtsi:370 */
			qdec {
				compatible = "st,stm32-qdec";    /* in zephyr\dts\arm\st\f4\stm32f4.dtsi:371 */
				status = "disabled";             /* in zephyr\dts\arm\st\f4\stm32f4.dtsi:372 */
				st,input-filter-level = < 0x0 >; /* in zephyr\dts\arm\st\f4\stm32f4.dtsi:373 */
			};
		};

		/* node '/soc/timers@40000400' defined in zephyr\dts\arm\st\f4\stm32f4.dtsi:377 */
		timers3: timers@40000400 {
			compatible = "st,stm32-timers"; /* in zephyr\dts\arm\st\f4\stm32f4.dtsi:378 */
			reg = < 0x40000400 0x400 >;     /* in zephyr\dts\arm\st\f4\stm32f4.dtsi:379 */
			clocks = < &rcc 0x40 0x2 >;     /* in zephyr\dts\arm\st\f4\stm32f4.dtsi:380 */
			resets = < &rctl 0x401 >;       /* in zephyr\dts\arm\st\f4\stm32f4.dtsi:381 */
			interrupts = < 0x1d 0x0 >;      /* in zephyr\dts\arm\st\f4\stm32f4.dtsi:382 */
			interrupt-names = "global";     /* in zephyr\dts\arm\st\f4\stm32f4.dtsi:383 */
			st,prescaler = < 0x0 >;         /* in zephyr\dts\arm\st\f4\stm32f4.dtsi:384 */
			status = "disabled";            /* in zephyr\dts\arm\st\f4\stm32f4.dtsi:385 */

			/* node '/soc/timers@40000400/pwm' defined in zephyr\dts\arm\st\f4\stm32f4.dtsi:387 */
			pwm {
				compatible = "st,stm32-pwm"; /* in zephyr\dts\arm\st\f4\stm32f4.dtsi:388 */
				status = "disabled";         /* in zephyr\dts\arm\st\f4\stm32f4.dtsi:389 */
				#pwm-cells = < 0x3 >;        /* in zephyr\dts\arm\st\f4\stm32f4.dtsi:390 */
			};

			/* node '/soc/timers@40000400/counter' defined in zephyr\dts\arm\st\f4\stm32f4.dtsi:393 */
			counter {
				compatible = "st,stm32-counter"; /* in zephyr\dts\arm\st\f4\stm32f4.dtsi:394 */
				status = "disabled";             /* in zephyr\dts\arm\st\f4\stm32f4.dtsi:395 */
			};

			/* node '/soc/timers@40000400/qdec' defined in zephyr\dts\arm\st\f4\stm32f4.dtsi:398 */
			qdec {
				compatible = "st,stm32-qdec";    /* in zephyr\dts\arm\st\f4\stm32f4.dtsi:399 */
				status = "disabled";             /* in zephyr\dts\arm\st\f4\stm32f4.dtsi:400 */
				st,input-filter-level = < 0x0 >; /* in zephyr\dts\arm\st\f4\stm32f4.dtsi:401 */
			};
		};

		/* node '/soc/timers@40000800' defined in zephyr\dts\arm\st\f4\stm32f4.dtsi:405 */
		timers4: timers@40000800 {
			compatible = "st,stm32-timers"; /* in zephyr\dts\arm\st\f4\stm32f4.dtsi:406 */
			reg = < 0x40000800 0x400 >;     /* in zephyr\dts\arm\st\f4\stm32f4.dtsi:407 */
			clocks = < &rcc 0x40 0x4 >;     /* in zephyr\dts\arm\st\f4\stm32f4.dtsi:408 */
			resets = < &rctl 0x402 >;       /* in zephyr\dts\arm\st\f4\stm32f4.dtsi:409 */
			interrupts = < 0x1e 0x0 >;      /* in zephyr\dts\arm\st\f4\stm32f4.dtsi:410 */
			interrupt-names = "global";     /* in zephyr\dts\arm\st\f4\stm32f4.dtsi:411 */
			st,prescaler = < 0x0 >;         /* in zephyr\dts\arm\st\f4\stm32f4.dtsi:412 */
			status = "disabled";            /* in zephyr\dts\arm\st\f4\stm32f4.dtsi:413 */

			/* node '/soc/timers@40000800/pwm' defined in zephyr\dts\arm\st\f4\stm32f4.dtsi:415 */
			pwm {
				compatible = "st,stm32-pwm"; /* in zephyr\dts\arm\st\f4\stm32f4.dtsi:416 */
				status = "disabled";         /* in zephyr\dts\arm\st\f4\stm32f4.dtsi:417 */
				#pwm-cells = < 0x3 >;        /* in zephyr\dts\arm\st\f4\stm32f4.dtsi:418 */
			};

			/* node '/soc/timers@40000800/counter' defined in zephyr\dts\arm\st\f4\stm32f4.dtsi:421 */
			counter {
				compatible = "st,stm32-counter"; /* in zephyr\dts\arm\st\f4\stm32f4.dtsi:422 */
				status = "disabled";             /* in zephyr\dts\arm\st\f4\stm32f4.dtsi:423 */
			};

			/* node '/soc/timers@40000800/qdec' defined in zephyr\dts\arm\st\f4\stm32f4.dtsi:426 */
			qdec {
				compatible = "st,stm32-qdec";    /* in zephyr\dts\arm\st\f4\stm32f4.dtsi:427 */
				status = "disabled";             /* in zephyr\dts\arm\st\f4\stm32f4.dtsi:428 */
				st,input-filter-level = < 0x0 >; /* in zephyr\dts\arm\st\f4\stm32f4.dtsi:429 */
			};
		};

		/* node '/soc/timers@40000c00' defined in zephyr\dts\arm\st\f4\stm32f4.dtsi:433 */
		timers5: timers@40000c00 {
			compatible = "st,stm32-timers"; /* in zephyr\dts\arm\st\f4\stm32f4.dtsi:434 */
			reg = < 0x40000c00 0x400 >;     /* in zephyr\dts\arm\st\f4\stm32f4.dtsi:435 */
			clocks = < &rcc 0x40 0x8 >;     /* in zephyr\dts\arm\st\f4\stm32f4.dtsi:436 */
			resets = < &rctl 0x403 >;       /* in zephyr\dts\arm\st\f4\stm32f4.dtsi:437 */
			interrupts = < 0x32 0x0 >;      /* in zephyr\dts\arm\st\f4\stm32f4.dtsi:438 */
			interrupt-names = "global";     /* in zephyr\dts\arm\st\f4\stm32f4.dtsi:439 */
			st,prescaler = < 0x0 >;         /* in zephyr\dts\arm\st\f4\stm32f4.dtsi:440 */
			status = "disabled";            /* in zephyr\dts\arm\st\f4\stm32f4.dtsi:441 */

			/* node '/soc/timers@40000c00/pwm' defined in zephyr\dts\arm\st\f4\stm32f4.dtsi:443 */
			pwm {
				compatible = "st,stm32-pwm"; /* in zephyr\dts\arm\st\f4\stm32f4.dtsi:444 */
				status = "disabled";         /* in zephyr\dts\arm\st\f4\stm32f4.dtsi:445 */
				#pwm-cells = < 0x3 >;        /* in zephyr\dts\arm\st\f4\stm32f4.dtsi:446 */
			};

			/* node '/soc/timers@40000c00/counter' defined in zephyr\dts\arm\st\f4\stm32f4.dtsi:449 */
			counter {
				compatible = "st,stm32-counter"; /* in zephyr\dts\arm\st\f4\stm32f4.dtsi:450 */
				status = "disabled";             /* in zephyr\dts\arm\st\f4\stm32f4.dtsi:451 */
			};

			/* node '/soc/timers@40000c00/qdec' defined in zephyr\dts\arm\st\f4\stm32f4.dtsi:454 */
			qdec {
				compatible = "st,stm32-qdec";    /* in zephyr\dts\arm\st\f4\stm32f4.dtsi:455 */
				status = "disabled";             /* in zephyr\dts\arm\st\f4\stm32f4.dtsi:456 */
				st,input-filter-level = < 0x0 >; /* in zephyr\dts\arm\st\f4\stm32f4.dtsi:457 */
			};
		};

		/* node '/soc/timers@40014000' defined in zephyr\dts\arm\st\f4\stm32f4.dtsi:461 */
		timers9: timers@40014000 {
			compatible = "st,stm32-timers"; /* in zephyr\dts\arm\st\f4\stm32f4.dtsi:462 */
			reg = < 0x40014000 0x400 >;     /* in zephyr\dts\arm\st\f4\stm32f4.dtsi:463 */
			clocks = < &rcc 0x44 0x10000 >; /* in zephyr\dts\arm\st\f4\stm32f4.dtsi:464 */
			resets = < &rctl 0x490 >;       /* in zephyr\dts\arm\st\f4\stm32f4.dtsi:465 */
			interrupts = < 0x18 0x0 >;      /* in zephyr\dts\arm\st\f4\stm32f4.dtsi:466 */
			interrupt-names = "global";     /* in zephyr\dts\arm\st\f4\stm32f4.dtsi:467 */
			st,prescaler = < 0x0 >;         /* in zephyr\dts\arm\st\f4\stm32f4.dtsi:468 */
			status = "disabled";            /* in zephyr\dts\arm\st\f4\stm32f4.dtsi:469 */

			/* node '/soc/timers@40014000/pwm' defined in zephyr\dts\arm\st\f4\stm32f4.dtsi:471 */
			pwm {
				compatible = "st,stm32-pwm"; /* in zephyr\dts\arm\st\f4\stm32f4.dtsi:472 */
				status = "disabled";         /* in zephyr\dts\arm\st\f4\stm32f4.dtsi:473 */
				#pwm-cells = < 0x3 >;        /* in zephyr\dts\arm\st\f4\stm32f4.dtsi:474 */
			};

			/* node '/soc/timers@40014000/counter' defined in zephyr\dts\arm\st\f4\stm32f4.dtsi:477 */
			counter {
				compatible = "st,stm32-counter"; /* in zephyr\dts\arm\st\f4\stm32f4.dtsi:478 */
				status = "disabled";             /* in zephyr\dts\arm\st\f4\stm32f4.dtsi:479 */
			};
		};

		/* node '/soc/timers@40014400' defined in zephyr\dts\arm\st\f4\stm32f4.dtsi:483 */
		timers10: timers@40014400 {
			compatible = "st,stm32-timers"; /* in zephyr\dts\arm\st\f4\stm32f4.dtsi:484 */
			reg = < 0x40014400 0x400 >;     /* in zephyr\dts\arm\st\f4\stm32f4.dtsi:485 */
			clocks = < &rcc 0x44 0x20000 >; /* in zephyr\dts\arm\st\f4\stm32f4.dtsi:486 */
			resets = < &rctl 0x491 >;       /* in zephyr\dts\arm\st\f4\stm32f4.dtsi:487 */
			interrupts = < 0x19 0x0 >;      /* in zephyr\dts\arm\st\f4\stm32f4.dtsi:488 */
			interrupt-names = "global";     /* in zephyr\dts\arm\st\f4\stm32f4.dtsi:489 */
			st,prescaler = < 0x0 >;         /* in zephyr\dts\arm\st\f4\stm32f4.dtsi:490 */
			status = "disabled";            /* in zephyr\dts\arm\st\f4\stm32f4.dtsi:491 */

			/* node '/soc/timers@40014400/pwm' defined in zephyr\dts\arm\st\f4\stm32f4.dtsi:493 */
			pwm {
				compatible = "st,stm32-pwm"; /* in zephyr\dts\arm\st\f4\stm32f4.dtsi:494 */
				status = "disabled";         /* in zephyr\dts\arm\st\f4\stm32f4.dtsi:495 */
				#pwm-cells = < 0x3 >;        /* in zephyr\dts\arm\st\f4\stm32f4.dtsi:496 */
			};

			/* node '/soc/timers@40014400/counter' defined in zephyr\dts\arm\st\f4\stm32f4.dtsi:499 */
			counter {
				compatible = "st,stm32-counter"; /* in zephyr\dts\arm\st\f4\stm32f4.dtsi:500 */
				status = "disabled";             /* in zephyr\dts\arm\st\f4\stm32f4.dtsi:501 */
			};
		};

		/* node '/soc/timers@40014800' defined in zephyr\dts\arm\st\f4\stm32f4.dtsi:505 */
		timers11: timers@40014800 {
			compatible = "st,stm32-timers"; /* in zephyr\dts\arm\st\f4\stm32f4.dtsi:506 */
			reg = < 0x40014800 0x400 >;     /* in zephyr\dts\arm\st\f4\stm32f4.dtsi:507 */
			clocks = < &rcc 0x44 0x40000 >; /* in zephyr\dts\arm\st\f4\stm32f4.dtsi:508 */
			resets = < &rctl 0x492 >;       /* in zephyr\dts\arm\st\f4\stm32f4.dtsi:509 */
			interrupts = < 0x1a 0x0 >;      /* in zephyr\dts\arm\st\f4\stm32f4.dtsi:510 */
			interrupt-names = "global";     /* in zephyr\dts\arm\st\f4\stm32f4.dtsi:511 */
			st,prescaler = < 0x0 >;         /* in zephyr\dts\arm\st\f4\stm32f4.dtsi:512 */
			status = "disabled";            /* in zephyr\dts\arm\st\f4\stm32f4.dtsi:513 */

			/* node '/soc/timers@40014800/pwm' defined in zephyr\dts\arm\st\f4\stm32f4.dtsi:515 */
			pwm {
				compatible = "st,stm32-pwm"; /* in zephyr\dts\arm\st\f4\stm32f4.dtsi:516 */
				status = "disabled";         /* in zephyr\dts\arm\st\f4\stm32f4.dtsi:517 */
				#pwm-cells = < 0x3 >;        /* in zephyr\dts\arm\st\f4\stm32f4.dtsi:518 */
			};

			/* node '/soc/timers@40014800/counter' defined in zephyr\dts\arm\st\f4\stm32f4.dtsi:521 */
			counter {
				compatible = "st,stm32-counter"; /* in zephyr\dts\arm\st\f4\stm32f4.dtsi:522 */
				status = "disabled";             /* in zephyr\dts\arm\st\f4\stm32f4.dtsi:523 */
			};
		};

		/* node '/soc/rtc@40002800' defined in zephyr\dts\arm\st\f4\stm32f4.dtsi:527 */
		rtc: rtc@40002800 {
			compatible = "st,stm32-rtc";       /* in zephyr\dts\arm\st\f4\stm32f4.dtsi:528 */
			reg = < 0x40002800 0x400 >;        /* in zephyr\dts\arm\st\f4\stm32f4.dtsi:529 */
			interrupts = < 0x29 0x0 >;         /* in zephyr\dts\arm\st\f4\stm32f4.dtsi:530 */
			prescaler = < 0x8000 >;            /* in zephyr\dts\arm\st\f4\stm32f4.dtsi:532 */
			alarms-count = < 0x2 >;            /* in zephyr\dts\arm\st\f4\stm32f4.dtsi:533 */
			alrm-exti-line = < 0x11 >;         /* in zephyr\dts\arm\st\f4\stm32f4.dtsi:534 */
			clocks = < &rcc 0x40 0x10000000 >,
			         < &rcc 0x3 0x10c80070 >;  /* in zephyr\boards\st\stm32f469i_disco\stm32f469i_disco.dts:128 */
			status = "okay";                   /* in zephyr\boards\st\stm32f469i_disco\stm32f469i_disco.dts:130 */

			/* node '/soc/rtc@40002800/backup_regs' defined in zephyr\dts\arm\st\f4\stm32f4.dtsi:537 */
			bbram: backup_regs {
				compatible = "st,stm32-bbram"; /* in zephyr\dts\arm\st\f4\stm32f4.dtsi:538 */
				st,backup-regs = < 0x14 >;     /* in zephyr\dts\arm\st\f4\stm32f4.dtsi:539 */
				status = "disabled";           /* in zephyr\dts\arm\st\f4\stm32f4.dtsi:540 */
			};
		};

		/* node '/soc/adc@40012000' defined in zephyr\dts\arm\st\f4\stm32f4.dtsi:544 */
		adc1: adc@40012000 {
			compatible = "st,stm32f4-adc",
			             "st,stm32-adc";                                 /* in zephyr\dts\arm\st\f4\stm32f4.dtsi:545 */
			reg = < 0x40012000 0x400 >;                                  /* in zephyr\dts\arm\st\f4\stm32f4.dtsi:546 */
			clocks = < &rcc 0x44 0x100 >;                                /* in zephyr\dts\arm\st\f4\stm32f4.dtsi:547 */
			interrupts = < 0x12 0x0 >;                                   /* in zephyr\dts\arm\st\f4\stm32f4.dtsi:548 */
			status = "disabled";                                         /* in zephyr\dts\arm\st\f4\stm32f4.dtsi:549 */
			#io-channel-cells = < 0x1 >;                                 /* in zephyr\dts\arm\st\f4\stm32f4.dtsi:550 */
			resolutions = < 0x607804 0x517804 0x427804 0x337804 >;       /* in zephyr\dts\arm\st\f4\stm32f4.dtsi:551 */
			sampling-times = < 0x3 0xf 0x1c 0x38 0x54 0x70 0x90 0x1e0 >; /* in zephyr\dts\arm\st\f4\stm32f4.dtsi:555 */
			st,adc-clock-source = "SYNC";                                /* in zephyr\dts\arm\st\f4\stm32f4.dtsi:556 */
			st,adc-sequencer = "FULLY_CONFIGURABLE";                     /* in zephyr\dts\arm\st\f4\stm32f4.dtsi:557 */
			st,adc-oversampler = "OVERSAMPLER_NONE";                     /* in zephyr\dts\arm\st\f4\stm32f4.dtsi:558 */
			phandle = < 0x1e >;                                          /* in zephyr\dts\arm\st\f4\stm32f427.dtsi:105 */
		};

		/* node '/soc/dma@40026000' defined in zephyr\dts\arm\st\f4\stm32f4.dtsi:561 */
		dma1: dma@40026000 {
			compatible = "st,stm32-dma-v1";                                                      /* in zephyr\dts\arm\st\f4\stm32f4.dtsi:562 */
			#dma-cells = < 0x4 >;                                                                /* in zephyr\dts\arm\st\f4\stm32f4.dtsi:563 */
			reg = < 0x40026000 0x400 >;                                                          /* in zephyr\dts\arm\st\f4\stm32f4.dtsi:564 */
			interrupts = < 0xb 0x0 0xc 0x0 0xd 0x0 0xe 0x0 0xf 0x0 0x10 0x0 0x11 0x0 0x2f 0x0 >; /* in zephyr\dts\arm\st\f4\stm32f4.dtsi:565 */
			clocks = < &rcc 0x30 0x200000 >;                                                     /* in zephyr\dts\arm\st\f4\stm32f4.dtsi:566 */
			status = "disabled";                                                                 /* in zephyr\dts\arm\st\f4\stm32f4.dtsi:567 */
			phandle = < 0x17 >;                                                                  /* in zephyr\dts\arm\st\f4\stm32f401.dtsi:58 */
		};

		/* node '/soc/dma@40026400' defined in zephyr\dts\arm\st\f4\stm32f4.dtsi:570 */
		dma2: dma@40026400 {
			compatible = "st,stm32-dma-v1";                                                           /* in zephyr\dts\arm\st\f4\stm32f4.dtsi:571 */
			#dma-cells = < 0x4 >;                                                                     /* in zephyr\dts\arm\st\f4\stm32f4.dtsi:572 */
			reg = < 0x40026400 0x400 >;                                                               /* in zephyr\dts\arm\st\f4\stm32f4.dtsi:573 */
			interrupts = < 0x38 0x0 0x39 0x0 0x3a 0x0 0x3b 0x0 0x3c 0x0 0x44 0x0 0x45 0x0 0x46 0x0 >; /* in zephyr\dts\arm\st\f4\stm32f4.dtsi:574 */
			clocks = < &rcc 0x30 0x400000 >;                                                          /* in zephyr\dts\arm\st\f4\stm32f4.dtsi:575 */
			st,mem2mem;                                                                               /* in zephyr\dts\arm\st\f4\stm32f4.dtsi:576 */
			status = "disabled";                                                                      /* in zephyr\dts\arm\st\f4\stm32f4.dtsi:577 */
		};

		/* node '/soc/sdmmc@40012c00' defined in zephyr\dts\arm\st\f4\stm32f4.dtsi:580 */
		sdmmc1: sdmmc@40012c00 {
			compatible = "st,stm32-sdmmc";                                                                     /* in zephyr\dts\arm\st\f4\stm32f4.dtsi:581 */
			reg = < 0x40012c00 0x400 >;                                                                        /* in zephyr\dts\arm\st\f4\stm32f4.dtsi:582 */
			resets = < &rctl 0x48b >;                                                                          /* in zephyr\dts\arm\st\f4\stm32f4.dtsi:585 */
			interrupts = < 0x31 0x0 >;                                                                         /* in zephyr\dts\arm\st\f4\stm32f4.dtsi:586 */
			clocks = < &rcc 0x44 0x800 >,
			         < &rcc 0x7 0x5b008c >;                                                                    /* in zephyr\boards\st\stm32f469i_disco\stm32f469i_disco.dts:134 */
			status = "okay";                                                                                   /* in zephyr\boards\st\stm32f469i_disco\stm32f469i_disco.dts:136 */
			pinctrl-0 = < &sdio_d0_pc8 &sdio_d1_pc9 &sdio_d2_pc10 &sdio_d3_pc11 &sdio_ck_pc12 &sdio_cmd_pd2 >; /* in zephyr\boards\st\stm32f469i_disco\stm32f469i_disco.dts:137 */
			pinctrl-names = "default";                                                                         /* in zephyr\boards\st\stm32f469i_disco\stm32f469i_disco.dts:143 */
			cd-gpios = < &gpiog 0x2 0x1 >;                                                                     /* in zephyr\boards\st\stm32f469i_disco\stm32f469i_disco.dts:144 */
			disk-name = "SD";                                                                                  /* in zephyr\boards\st\stm32f469i_disco\stm32f469i_disco.dts:145 */
		};

		/* node '/soc/spi@40003800' defined in zephyr\dts\arm\st\f4\stm32f401.dtsi:21 */
		spi2: arduino_spi: spi@40003800 {
			compatible = "st,stm32-spi";                                   /* in zephyr\dts\arm\st\f4\stm32f401.dtsi:22 */
			#address-cells = < 0x1 >;                                      /* in zephyr\dts\arm\st\f4\stm32f401.dtsi:23 */
			#size-cells = < 0x0 >;                                         /* in zephyr\dts\arm\st\f4\stm32f401.dtsi:24 */
			reg = < 0x40003800 0x400 >;                                    /* in zephyr\dts\arm\st\f4\stm32f401.dtsi:25 */
			clocks = < &rcc 0x40 0x4000 >;                                 /* in zephyr\dts\arm\st\f4\stm32f401.dtsi:26 */
			interrupts = < 0x24 0x5 >;                                     /* in zephyr\dts\arm\st\f4\stm32f401.dtsi:27 */
			pinctrl-0 = < &spi2_sck_pd3 &spi2_miso_pb14 &spi2_mosi_pb15 >; /* in zephyr\boards\st\stm32f469i_disco\stm32f469i_disco.dts:115 */
			pinctrl-names = "default";                                     /* in zephyr\boards\st\stm32f469i_disco\stm32f469i_disco.dts:116 */
			cs-gpios = < &gpioh 0x6 0x11 >;                                /* in zephyr\boards\st\stm32f469i_disco\stm32f469i_disco.dts:117 */
			status = "okay";                                               /* in zephyr\boards\st\stm32f469i_disco\stm32f469i_disco.dts:118 */
		};

		/* node '/soc/spi@40003c00' defined in zephyr\dts\arm\st\f4\stm32f401.dtsi:31 */
		spi3: spi@40003c00 {
			compatible = "st,stm32-spi";   /* in zephyr\dts\arm\st\f4\stm32f401.dtsi:32 */
			#address-cells = < 0x1 >;      /* in zephyr\dts\arm\st\f4\stm32f401.dtsi:33 */
			#size-cells = < 0x0 >;         /* in zephyr\dts\arm\st\f4\stm32f401.dtsi:34 */
			reg = < 0x40003c00 0x400 >;    /* in zephyr\dts\arm\st\f4\stm32f401.dtsi:35 */
			clocks = < &rcc 0x40 0x8000 >; /* in zephyr\dts\arm\st\f4\stm32f401.dtsi:36 */
			interrupts = < 0x33 0x5 >;     /* in zephyr\dts\arm\st\f4\stm32f401.dtsi:37 */
			status = "disabled";           /* in zephyr\dts\arm\st\f4\stm32f401.dtsi:38 */
		};

		/* node '/soc/spi@40013400' defined in zephyr\dts\arm\st\f4\stm32f401.dtsi:41 */
		spi4: spi@40013400 {
			compatible = "st,stm32-spi";   /* in zephyr\dts\arm\st\f4\stm32f427.dtsi:54 */
			#address-cells = < 0x1 >;      /* in zephyr\dts\arm\st\f4\stm32f427.dtsi:55 */
			#size-cells = < 0x0 >;         /* in zephyr\dts\arm\st\f4\stm32f427.dtsi:56 */
			reg = < 0x40013400 0x400 >;    /* in zephyr\dts\arm\st\f4\stm32f427.dtsi:57 */
			clocks = < &rcc 0x44 0x2000 >; /* in zephyr\dts\arm\st\f4\stm32f427.dtsi:58 */
			interrupts = < 0x54 0x5 >;     /* in zephyr\dts\arm\st\f4\stm32f427.dtsi:59 */
			status = "disabled";           /* in zephyr\dts\arm\st\f4\stm32f427.dtsi:60 */
		};

		/* node '/soc/i2s@40003800' defined in zephyr\dts\arm\st\f4\stm32f401.dtsi:51 */
		i2s2: i2s@40003800 {
			compatible = "st,stm32-i2s";                                /* in zephyr\dts\arm\st\f4\stm32f401.dtsi:52 */
			#address-cells = < 0x1 >;                                   /* in zephyr\dts\arm\st\f4\stm32f401.dtsi:53 */
			#size-cells = < 0x0 >;                                      /* in zephyr\dts\arm\st\f4\stm32f401.dtsi:54 */
			reg = < 0x40003800 0x400 >;                                 /* in zephyr\dts\arm\st\f4\stm32f401.dtsi:55 */
			clocks = < &rcc 0x40 0x4000 >;                              /* in zephyr\dts\arm\st\f4\stm32f401.dtsi:56 */
			interrupts = < 0x24 0x5 >;                                  /* in zephyr\dts\arm\st\f4\stm32f401.dtsi:57 */
			dmas = < &dma1 0x4 0x0 0x400 0x3 &dma1 0x3 0x0 0x400 0x3 >; /* in zephyr\dts\arm\st\f4\stm32f401.dtsi:58 */
			dma-names = "tx",
			            "rx";                                           /* in zephyr\dts\arm\st\f4\stm32f401.dtsi:60 */
			status = "disabled";                                        /* in zephyr\dts\arm\st\f4\stm32f401.dtsi:61 */
		};

		/* node '/soc/i2s@40003c00' defined in zephyr\dts\arm\st\f4\stm32f401.dtsi:64 */
		i2s3: i2s@40003c00 {
			compatible = "st,stm32-i2s";                                /* in zephyr\dts\arm\st\f4\stm32f401.dtsi:65 */
			#address-cells = < 0x1 >;                                   /* in zephyr\dts\arm\st\f4\stm32f401.dtsi:66 */
			#size-cells = < 0x0 >;                                      /* in zephyr\dts\arm\st\f4\stm32f401.dtsi:67 */
			reg = < 0x40003c00 0x400 >;                                 /* in zephyr\dts\arm\st\f4\stm32f401.dtsi:68 */
			clocks = < &rcc 0x40 0x8000 >;                              /* in zephyr\dts\arm\st\f4\stm32f401.dtsi:69 */
			interrupts = < 0x33 0x5 >;                                  /* in zephyr\dts\arm\st\f4\stm32f401.dtsi:70 */
			dmas = < &dma1 0x5 0x0 0x400 0x3 &dma1 0x0 0x0 0x400 0x3 >; /* in zephyr\dts\arm\st\f4\stm32f401.dtsi:71 */
			dma-names = "tx",
			            "rx";                                           /* in zephyr\dts\arm\st\f4\stm32f401.dtsi:73 */
			status = "disabled";                                        /* in zephyr\dts\arm\st\f4\stm32f401.dtsi:74 */
		};

		/* node '/soc/serial@40004800' defined in zephyr\dts\arm\st\f4\stm32f405.dtsi:46 */
		usart3: serial@40004800 {
			compatible = "st,stm32-usart",
			             "st,stm32-uart";                    /* in zephyr\dts\arm\st\f4\stm32f405.dtsi:47 */
			reg = < 0x40004800 0x400 >;                      /* in zephyr\dts\arm\st\f4\stm32f405.dtsi:48 */
			clocks = < &rcc 0x40 0x40000 >;                  /* in zephyr\dts\arm\st\f4\stm32f405.dtsi:49 */
			resets = < &rctl 0x412 >;                        /* in zephyr\dts\arm\st\f4\stm32f405.dtsi:50 */
			interrupts = < 0x27 0x0 >;                       /* in zephyr\dts\arm\st\f4\stm32f405.dtsi:51 */
			pinctrl-0 = < &usart3_tx_pb10 &usart3_rx_pb11 >; /* in zephyr\boards\st\stm32f469i_disco\stm32f469i_disco.dts:95 */
			pinctrl-names = "default";                       /* in zephyr\boards\st\stm32f469i_disco\stm32f469i_disco.dts:96 */
			current-speed = < 0x1c200 >;                     /* in zephyr\boards\st\stm32f469i_disco\stm32f469i_disco.dts:97 */
			status = "okay";                                 /* in zephyr\boards\st\stm32f469i_disco\stm32f469i_disco.dts:98 */
		};

		/* node '/soc/serial@40004c00' defined in zephyr\dts\arm\st\f4\stm32f405.dtsi:55 */
		uart4: serial@40004c00 {
			compatible = "st,stm32-uart";   /* in zephyr\dts\arm\st\f4\stm32f405.dtsi:56 */
			reg = < 0x40004c00 0x400 >;     /* in zephyr\dts\arm\st\f4\stm32f405.dtsi:57 */
			clocks = < &rcc 0x40 0x80000 >; /* in zephyr\dts\arm\st\f4\stm32f405.dtsi:58 */
			resets = < &rctl 0x413 >;       /* in zephyr\dts\arm\st\f4\stm32f405.dtsi:59 */
			interrupts = < 0x34 0x0 >;      /* in zephyr\dts\arm\st\f4\stm32f405.dtsi:60 */
			status = "disabled";            /* in zephyr\dts\arm\st\f4\stm32f405.dtsi:61 */
		};

		/* node '/soc/serial@40005000' defined in zephyr\dts\arm\st\f4\stm32f405.dtsi:64 */
		uart5: serial@40005000 {
			compatible = "st,stm32-uart";    /* in zephyr\dts\arm\st\f4\stm32f405.dtsi:65 */
			reg = < 0x40005000 0x400 >;      /* in zephyr\dts\arm\st\f4\stm32f405.dtsi:66 */
			clocks = < &rcc 0x40 0x100000 >; /* in zephyr\dts\arm\st\f4\stm32f405.dtsi:67 */
			resets = < &rctl 0x414 >;        /* in zephyr\dts\arm\st\f4\stm32f405.dtsi:68 */
			interrupts = < 0x35 0x0 >;       /* in zephyr\dts\arm\st\f4\stm32f405.dtsi:69 */
			status = "disabled";             /* in zephyr\dts\arm\st\f4\stm32f405.dtsi:70 */
		};

		/* node '/soc/timers@40001000' defined in zephyr\dts\arm\st\f4\stm32f405.dtsi:73 */
		timers6: timers@40001000 {
			compatible = "st,stm32-timers"; /* in zephyr\dts\arm\st\f4\stm32f405.dtsi:74 */
			reg = < 0x40001000 0x400 >;     /* in zephyr\dts\arm\st\f4\stm32f405.dtsi:75 */
			clocks = < &rcc 0x40 0x10 >;    /* in zephyr\dts\arm\st\f4\stm32f405.dtsi:76 */
			resets = < &rctl 0x404 >;       /* in zephyr\dts\arm\st\f4\stm32f405.dtsi:77 */
			interrupts = < 0x36 0x0 >;      /* in zephyr\dts\arm\st\f4\stm32f405.dtsi:78 */
			interrupt-names = "global";     /* in zephyr\dts\arm\st\f4\stm32f405.dtsi:79 */
			st,prescaler = < 0x0 >;         /* in zephyr\dts\arm\st\f4\stm32f405.dtsi:80 */
			status = "disabled";            /* in zephyr\dts\arm\st\f4\stm32f405.dtsi:81 */

			/* node '/soc/timers@40001000/counter' defined in zephyr\dts\arm\st\f4\stm32f405.dtsi:83 */
			counter {
				compatible = "st,stm32-counter"; /* in zephyr\dts\arm\st\f4\stm32f405.dtsi:84 */
				status = "disabled";             /* in zephyr\dts\arm\st\f4\stm32f405.dtsi:85 */
			};
		};

		/* node '/soc/timers@40001400' defined in zephyr\dts\arm\st\f4\stm32f405.dtsi:89 */
		timers7: timers@40001400 {
			compatible = "st,stm32-timers"; /* in zephyr\dts\arm\st\f4\stm32f405.dtsi:90 */
			reg = < 0x40001400 0x400 >;     /* in zephyr\dts\arm\st\f4\stm32f405.dtsi:91 */
			clocks = < &rcc 0x40 0x20 >;    /* in zephyr\dts\arm\st\f4\stm32f405.dtsi:92 */
			resets = < &rctl 0x405 >;       /* in zephyr\dts\arm\st\f4\stm32f405.dtsi:93 */
			interrupts = < 0x37 0x0 >;      /* in zephyr\dts\arm\st\f4\stm32f405.dtsi:94 */
			interrupt-names = "global";     /* in zephyr\dts\arm\st\f4\stm32f405.dtsi:95 */
			st,prescaler = < 0x0 >;         /* in zephyr\dts\arm\st\f4\stm32f405.dtsi:96 */
			status = "disabled";            /* in zephyr\dts\arm\st\f4\stm32f405.dtsi:97 */

			/* node '/soc/timers@40001400/counter' defined in zephyr\dts\arm\st\f4\stm32f405.dtsi:99 */
			counter {
				compatible = "st,stm32-counter"; /* in zephyr\dts\arm\st\f4\stm32f405.dtsi:100 */
				status = "disabled";             /* in zephyr\dts\arm\st\f4\stm32f405.dtsi:101 */
			};
		};

		/* node '/soc/timers@40010400' defined in zephyr\dts\arm\st\f4\stm32f405.dtsi:105 */
		timers8: timers@40010400 {
			compatible = "st,stm32-timers"; /* in zephyr\dts\arm\st\f4\stm32f405.dtsi:106 */
			reg = < 0x40010400 0x400 >;     /* in zephyr\dts\arm\st\f4\stm32f405.dtsi:107 */
			clocks = < &rcc 0x44 0x2 >;     /* in zephyr\dts\arm\st\f4\stm32f405.dtsi:108 */
			resets = < &rctl 0x481 >;       /* in zephyr\dts\arm\st\f4\stm32f405.dtsi:109 */
			interrupts = < 0x2b 0x0 >,
			             < 0x2c 0x0 >,
			             < 0x2d 0x0 >,
			             < 0x2e 0x0 >;      /* in zephyr\dts\arm\st\f4\stm32f405.dtsi:110 */
			interrupt-names = "brk",
			                  "up",
			                  "trgcom",
			                  "cc";         /* in zephyr\dts\arm\st\f4\stm32f405.dtsi:111 */
			st,prescaler = < 0x0 >;         /* in zephyr\dts\arm\st\f4\stm32f405.dtsi:112 */
			status = "disabled";            /* in zephyr\dts\arm\st\f4\stm32f405.dtsi:113 */

			/* node '/soc/timers@40010400/pwm' defined in zephyr\dts\arm\st\f4\stm32f405.dtsi:115 */
			pwm {
				compatible = "st,stm32-pwm"; /* in zephyr\dts\arm\st\f4\stm32f405.dtsi:116 */
				status = "disabled";         /* in zephyr\dts\arm\st\f4\stm32f405.dtsi:117 */
				#pwm-cells = < 0x3 >;        /* in zephyr\dts\arm\st\f4\stm32f405.dtsi:118 */
			};

			/* node '/soc/timers@40010400/qdec' defined in zephyr\dts\arm\st\f4\stm32f405.dtsi:121 */
			qdec {
				compatible = "st,stm32-qdec";    /* in zephyr\dts\arm\st\f4\stm32f405.dtsi:122 */
				status = "disabled";             /* in zephyr\dts\arm\st\f4\stm32f405.dtsi:123 */
				st,input-filter-level = < 0x0 >; /* in zephyr\dts\arm\st\f4\stm32f405.dtsi:124 */
			};
		};

		/* node '/soc/timers@40001800' defined in zephyr\dts\arm\st\f4\stm32f405.dtsi:128 */
		timers12: timers@40001800 {
			compatible = "st,stm32-timers"; /* in zephyr\dts\arm\st\f4\stm32f405.dtsi:129 */
			reg = < 0x40001800 0x400 >;     /* in zephyr\dts\arm\st\f4\stm32f405.dtsi:130 */
			clocks = < &rcc 0x40 0x40 >;    /* in zephyr\dts\arm\st\f4\stm32f405.dtsi:131 */
			resets = < &rctl 0x406 >;       /* in zephyr\dts\arm\st\f4\stm32f405.dtsi:132 */
			interrupts = < 0x2b 0x0 >;      /* in zephyr\dts\arm\st\f4\stm32f405.dtsi:133 */
			interrupt-names = "global";     /* in zephyr\dts\arm\st\f4\stm32f405.dtsi:134 */
			st,prescaler = < 0x0 >;         /* in zephyr\dts\arm\st\f4\stm32f405.dtsi:135 */
			status = "disabled";            /* in zephyr\dts\arm\st\f4\stm32f405.dtsi:136 */

			/* node '/soc/timers@40001800/pwm' defined in zephyr\dts\arm\st\f4\stm32f405.dtsi:138 */
			pwm {
				compatible = "st,stm32-pwm"; /* in zephyr\dts\arm\st\f4\stm32f405.dtsi:139 */
				status = "disabled";         /* in zephyr\dts\arm\st\f4\stm32f405.dtsi:140 */
				#pwm-cells = < 0x3 >;        /* in zephyr\dts\arm\st\f4\stm32f405.dtsi:141 */
			};

			/* node '/soc/timers@40001800/counter' defined in zephyr\dts\arm\st\f4\stm32f405.dtsi:144 */
			counter {
				compatible = "st,stm32-counter"; /* in zephyr\dts\arm\st\f4\stm32f405.dtsi:145 */
				status = "disabled";             /* in zephyr\dts\arm\st\f4\stm32f405.dtsi:146 */
			};
		};

		/* node '/soc/timers@40001c00' defined in zephyr\dts\arm\st\f4\stm32f405.dtsi:150 */
		timers13: timers@40001c00 {
			compatible = "st,stm32-timers"; /* in zephyr\dts\arm\st\f4\stm32f405.dtsi:151 */
			reg = < 0x40001c00 0x400 >;     /* in zephyr\dts\arm\st\f4\stm32f405.dtsi:152 */
			clocks = < &rcc 0x40 0x80 >;    /* in zephyr\dts\arm\st\f4\stm32f405.dtsi:153 */
			resets = < &rctl 0x407 >;       /* in zephyr\dts\arm\st\f4\stm32f405.dtsi:154 */
			interrupts = < 0x2c 0x0 >;      /* in zephyr\dts\arm\st\f4\stm32f405.dtsi:155 */
			interrupt-names = "global";     /* in zephyr\dts\arm\st\f4\stm32f405.dtsi:156 */
			st,prescaler = < 0x0 >;         /* in zephyr\dts\arm\st\f4\stm32f405.dtsi:157 */
			status = "disabled";            /* in zephyr\dts\arm\st\f4\stm32f405.dtsi:158 */

			/* node '/soc/timers@40001c00/pwm' defined in zephyr\dts\arm\st\f4\stm32f405.dtsi:160 */
			pwm {
				compatible = "st,stm32-pwm"; /* in zephyr\dts\arm\st\f4\stm32f405.dtsi:161 */
				status = "disabled";         /* in zephyr\dts\arm\st\f4\stm32f405.dtsi:162 */
				#pwm-cells = < 0x3 >;        /* in zephyr\dts\arm\st\f4\stm32f405.dtsi:163 */
			};

			/* node '/soc/timers@40001c00/counter' defined in zephyr\dts\arm\st\f4\stm32f405.dtsi:166 */
			counter {
				compatible = "st,stm32-counter"; /* in zephyr\dts\arm\st\f4\stm32f405.dtsi:167 */
				status = "disabled";             /* in zephyr\dts\arm\st\f4\stm32f405.dtsi:168 */
			};
		};

		/* node '/soc/timers@40002000' defined in zephyr\dts\arm\st\f4\stm32f405.dtsi:172 */
		timers14: timers@40002000 {
			compatible = "st,stm32-timers"; /* in zephyr\dts\arm\st\f4\stm32f405.dtsi:173 */
			reg = < 0x40002000 0x400 >;     /* in zephyr\dts\arm\st\f4\stm32f405.dtsi:174 */
			clocks = < &rcc 0x40 0x100 >;   /* in zephyr\dts\arm\st\f4\stm32f405.dtsi:175 */
			resets = < &rctl 0x408 >;       /* in zephyr\dts\arm\st\f4\stm32f405.dtsi:176 */
			interrupts = < 0x2d 0x0 >;      /* in zephyr\dts\arm\st\f4\stm32f405.dtsi:177 */
			interrupt-names = "global";     /* in zephyr\dts\arm\st\f4\stm32f405.dtsi:178 */
			st,prescaler = < 0x0 >;         /* in zephyr\dts\arm\st\f4\stm32f405.dtsi:179 */
			status = "disabled";            /* in zephyr\dts\arm\st\f4\stm32f405.dtsi:180 */

			/* node '/soc/timers@40002000/pwm' defined in zephyr\dts\arm\st\f4\stm32f405.dtsi:182 */
			pwm {
				compatible = "st,stm32-pwm"; /* in zephyr\dts\arm\st\f4\stm32f405.dtsi:183 */
				status = "disabled";         /* in zephyr\dts\arm\st\f4\stm32f405.dtsi:184 */
				#pwm-cells = < 0x3 >;        /* in zephyr\dts\arm\st\f4\stm32f405.dtsi:185 */
			};

			/* node '/soc/timers@40002000/counter' defined in zephyr\dts\arm\st\f4\stm32f405.dtsi:188 */
			counter {
				compatible = "st,stm32-counter"; /* in zephyr\dts\arm\st\f4\stm32f405.dtsi:189 */
				status = "disabled";             /* in zephyr\dts\arm\st\f4\stm32f405.dtsi:190 */
			};
		};

		/* node '/soc/usb@40040000' defined in zephyr\dts\arm\st\f4\stm32f405.dtsi:194 */
		usbotg_hs: usb@40040000 {
			compatible = "st,stm32-otghs";     /* in zephyr\dts\arm\st\f4\stm32f405.dtsi:195 */
			reg = < 0x40040000 0x40000 >;      /* in zephyr\dts\arm\st\f4\stm32f405.dtsi:196 */
			interrupts = < 0x4d 0x0 >,
			             < 0x4a 0x0 >,
			             < 0x4b 0x0 >;         /* in zephyr\dts\arm\st\f4\stm32f405.dtsi:197 */
			interrupt-names = "otghs",
			                  "ep1_out",
			                  "ep1_in";        /* in zephyr\dts\arm\st\f4\stm32f405.dtsi:198 */
			ram-size = < 0x1000 >;             /* in zephyr\dts\arm\st\f4\stm32f405.dtsi:200 */
			maximum-speed = "full-speed";      /* in zephyr\dts\arm\st\f4\stm32f405.dtsi:201 */
			phys = < &otghs_fs_phy >;          /* in zephyr\dts\arm\st\f4\stm32f405.dtsi:202 */
			clocks = < &rcc 0x30 0x20000000 >,
			         < &rcc 0x7 0xff >;        /* in zephyr\dts\arm\st\f4\stm32f405.dtsi:203 */
			status = "disabled";               /* in zephyr\dts\arm\st\f4\stm32f405.dtsi:205 */
			num-bidir-endpoints = < 0x9 >;     /* in zephyr\dts\arm\st\f4\stm32f469.dtsi:25 */
		};

		/* node '/soc/can@40006400' defined in zephyr\dts\arm\st\f4\stm32f405.dtsi:208 */
		can1: can@40006400 {
			compatible = "st,stm32-bxcan";    /* in zephyr\dts\arm\st\f4\stm32f405.dtsi:209 */
			reg = < 0x40006400 0x400 >;       /* in zephyr\dts\arm\st\f4\stm32f405.dtsi:210 */
			interrupts = < 0x13 0x0 >,
			             < 0x14 0x0 >,
			             < 0x15 0x0 >,
			             < 0x16 0x0 >;        /* in zephyr\dts\arm\st\f4\stm32f405.dtsi:211 */
			interrupt-names = "TX",
			                  "RX0",
			                  "RX1",
			                  "SCE";          /* in zephyr\dts\arm\st\f4\stm32f405.dtsi:212 */
			clocks = < &rcc 0x40 0x2000000 >; /* in zephyr\dts\arm\st\f4\stm32f405.dtsi:213 */
			status = "disabled";              /* in zephyr\dts\arm\st\f4\stm32f405.dtsi:214 */
		};

		/* node '/soc/can@40006800' defined in zephyr\dts\arm\st\f4\stm32f405.dtsi:217 */
		can2: can@40006800 {
			compatible = "st,stm32-bxcan";    /* in zephyr\dts\arm\st\f4\stm32f405.dtsi:218 */
			reg = < 0x40006800 0x400 >;       /* in zephyr\dts\arm\st\f4\stm32f405.dtsi:219 */
			interrupts = < 0x3f 0x0 >,
			             < 0x40 0x0 >,
			             < 0x41 0x0 >,
			             < 0x42 0x0 >;        /* in zephyr\dts\arm\st\f4\stm32f405.dtsi:220 */
			interrupt-names = "TX",
			                  "RX0",
			                  "RX1",
			                  "SCE";          /* in zephyr\dts\arm\st\f4\stm32f405.dtsi:221 */
			clocks = < &rcc 0x40 0x6000000 >; /* in zephyr\dts\arm\st\f4\stm32f405.dtsi:223 */
			master-can-reg = < 0x40006400 >;  /* in zephyr\dts\arm\st\f4\stm32f405.dtsi:224 */
			status = "disabled";              /* in zephyr\dts\arm\st\f4\stm32f405.dtsi:225 */
		};

		/* node '/soc/rng@50060800' defined in zephyr\dts\arm\st\f4\stm32f405.dtsi:228 */
		rng: rng@50060800 {
			compatible = "st,stm32-rng"; /* in zephyr\dts\arm\st\f4\stm32f405.dtsi:229 */
			reg = < 0x50060800 0x400 >;  /* in zephyr\dts\arm\st\f4\stm32f405.dtsi:230 */
			interrupts = < 0x50 0x0 >;   /* in zephyr\dts\arm\st\f4\stm32f405.dtsi:231 */
			clocks = < &rcc 0x34 0x40 >; /* in zephyr\dts\arm\st\f4\stm32f405.dtsi:232 */
			status = "disabled";         /* in zephyr\dts\arm\st\f4\stm32f405.dtsi:233 */
		};

		/* node '/soc/memory@40024000' defined in zephyr\dts\arm\st\f4\stm32f405.dtsi:236 */
		backup_sram: memory@40024000 {
			compatible = "zephyr,memory-region",
			             "st,stm32-backup-sram";  /* in zephyr\dts\arm\st\f4\stm32f405.dtsi:237 */
			reg = < 0x40024000 0x1000 >;          /* in zephyr\dts\arm\st\f4\stm32f405.dtsi:238 */
			clocks = < &rcc 0x30 0x40000 >;       /* in zephyr\dts\arm\st\f4\stm32f405.dtsi:239 */
			zephyr,memory-region = "BACKUP_SRAM"; /* in zephyr\dts\arm\st\f4\stm32f405.dtsi:240 */
			status = "disabled";                  /* in zephyr\dts\arm\st\f4\stm32f405.dtsi:241 */
		};

		/* node '/soc/adc@40012100' defined in zephyr\dts\arm\st\f4\stm32f405.dtsi:244 */
		adc2: adc@40012100 {
			compatible = "st,stm32-adc";                                 /* in zephyr\dts\arm\st\f4\stm32f405.dtsi:245 */
			reg = < 0x40012100 0x50 >;                                   /* in zephyr\dts\arm\st\f4\stm32f405.dtsi:246 */
			clocks = < &rcc 0x44 0x200 >;                                /* in zephyr\dts\arm\st\f4\stm32f405.dtsi:247 */
			interrupts = < 0x12 0x0 >;                                   /* in zephyr\dts\arm\st\f4\stm32f405.dtsi:248 */
			status = "disabled";                                         /* in zephyr\dts\arm\st\f4\stm32f405.dtsi:249 */
			#io-channel-cells = < 0x1 >;                                 /* in zephyr\dts\arm\st\f4\stm32f405.dtsi:250 */
			resolutions = < 0x607804 0x517804 0x427804 0x337804 >;       /* in zephyr\dts\arm\st\f4\stm32f405.dtsi:251 */
			sampling-times = < 0x3 0xf 0x1c 0x38 0x54 0x70 0x90 0x1e0 >; /* in zephyr\dts\arm\st\f4\stm32f405.dtsi:255 */
			st,adc-clock-source = "SYNC";                                /* in zephyr\dts\arm\st\f4\stm32f405.dtsi:256 */
			st,adc-sequencer = "FULLY_CONFIGURABLE";                     /* in zephyr\dts\arm\st\f4\stm32f405.dtsi:257 */
			st,adc-oversampler = "OVERSAMPLER_NONE";                     /* in zephyr\dts\arm\st\f4\stm32f405.dtsi:258 */
		};

		/* node '/soc/adc@40012200' defined in zephyr\dts\arm\st\f4\stm32f405.dtsi:261 */
		adc3: adc@40012200 {
			compatible = "st,stm32-adc";                                 /* in zephyr\dts\arm\st\f4\stm32f405.dtsi:262 */
			reg = < 0x40012200 0x50 >;                                   /* in zephyr\dts\arm\st\f4\stm32f405.dtsi:263 */
			clocks = < &rcc 0x44 0x400 >;                                /* in zephyr\dts\arm\st\f4\stm32f405.dtsi:264 */
			interrupts = < 0x12 0x0 >;                                   /* in zephyr\dts\arm\st\f4\stm32f405.dtsi:265 */
			status = "disabled";                                         /* in zephyr\dts\arm\st\f4\stm32f405.dtsi:266 */
			#io-channel-cells = < 0x1 >;                                 /* in zephyr\dts\arm\st\f4\stm32f405.dtsi:267 */
			resolutions = < 0x607804 0x517804 0x427804 0x337804 >;       /* in zephyr\dts\arm\st\f4\stm32f405.dtsi:268 */
			sampling-times = < 0x3 0xf 0x1c 0x38 0x54 0x70 0x90 0x1e0 >; /* in zephyr\dts\arm\st\f4\stm32f405.dtsi:272 */
			st,adc-clock-source = "SYNC";                                /* in zephyr\dts\arm\st\f4\stm32f405.dtsi:273 */
			st,adc-sequencer = "FULLY_CONFIGURABLE";                     /* in zephyr\dts\arm\st\f4\stm32f405.dtsi:274 */
			st,adc-oversampler = "OVERSAMPLER_NONE";                     /* in zephyr\dts\arm\st\f4\stm32f405.dtsi:275 */
		};

		/* node '/soc/dac@40007400' defined in zephyr\dts\arm\st\f4\stm32f405.dtsi:278 */
		dac1: dac@40007400 {
			compatible = "st,stm32-dac";       /* in zephyr\dts\arm\st\f4\stm32f429.dtsi:15 */
			reg = < 0x40007400 0x400 >;        /* in zephyr\dts\arm\st\f4\stm32f429.dtsi:16 */
			clocks = < &rcc 0x40 0x20000000 >; /* in zephyr\dts\arm\st\f4\stm32f429.dtsi:17 */
			status = "disabled";               /* in zephyr\dts\arm\st\f4\stm32f429.dtsi:18 */
			#io-channel-cells = < 0x1 >;       /* in zephyr\dts\arm\st\f4\stm32f429.dtsi:19 */
		};

		/* node '/soc/ethernet@40028000' defined in zephyr\dts\arm\st\f4\stm32f407.dtsi:13 */
		ethernet@40028000 {
			reg = < 0x40028000 0x8000 >;                 /* in zephyr\dts\arm\st\f4\stm32f407.dtsi:14 */
			compatible = "st,stm32-ethernet-controller"; /* in zephyr\dts\arm\st\f4\stm32f407.dtsi:15 */
			clock-names = "stm-eth";                     /* in zephyr\dts\arm\st\f4\stm32f407.dtsi:16 */
			clocks = < &rcc 0x30 0x2000000 >;            /* in zephyr\dts\arm\st\f4\stm32f407.dtsi:17 */

			/* node '/soc/ethernet@40028000/ethernet' defined in zephyr\dts\arm\st\f4\stm32f407.dtsi:19 */
			mac: ethernet {
				compatible = "st,stm32-ethernet";  /* in zephyr\dts\arm\st\f4\stm32f407.dtsi:20 */
				interrupts = < 0x3d 0x0 >;         /* in zephyr\dts\arm\st\f4\stm32f407.dtsi:21 */
				clock-names = "mac-clk-tx",
				              "mac-clk-rx",
				              "mac-clk-ptp";       /* in zephyr\dts\arm\st\f4\stm32f407.dtsi:22 */
				clocks = < &rcc 0x30 0x4000000 >,
				         < &rcc 0x30 0x8000000 >,
				         < &rcc 0x30 0x10000000 >; /* in zephyr\dts\arm\st\f4\stm32f407.dtsi:24 */
				status = "disabled";               /* in zephyr\dts\arm\st\f4\stm32f407.dtsi:27 */
			};

			/* node '/soc/ethernet@40028000/mdio' defined in zephyr\dts\arm\st\f4\stm32f407.dtsi:30 */
			mdio: mdio {
				compatible = "st,stm32-mdio"; /* in zephyr\dts\arm\st\f4\stm32f407.dtsi:31 */
				#address-cells = < 0x1 >;     /* in zephyr\dts\arm\st\f4\stm32f407.dtsi:32 */
				#size-cells = < 0x0 >;        /* in zephyr\dts\arm\st\f4\stm32f407.dtsi:33 */
				status = "disabled";          /* in zephyr\dts\arm\st\f4\stm32f407.dtsi:34 */
			};
		};

		/* node '/soc/serial@40007800' defined in zephyr\dts\arm\st\f4\stm32f427.dtsi:35 */
		uart7: serial@40007800 {
			compatible = "st,stm32-uart";      /* in zephyr\dts\arm\st\f4\stm32f427.dtsi:36 */
			reg = < 0x40007800 0x400 >;        /* in zephyr\dts\arm\st\f4\stm32f427.dtsi:37 */
			clocks = < &rcc 0x40 0x40000000 >; /* in zephyr\dts\arm\st\f4\stm32f427.dtsi:38 */
			resets = < &rctl 0x41e >;          /* in zephyr\dts\arm\st\f4\stm32f427.dtsi:39 */
			interrupts = < 0x52 0x0 >;         /* in zephyr\dts\arm\st\f4\stm32f427.dtsi:40 */
			status = "disabled";               /* in zephyr\dts\arm\st\f4\stm32f427.dtsi:41 */
		};

		/* node '/soc/serial@40007c00' defined in zephyr\dts\arm\st\f4\stm32f427.dtsi:44 */
		uart8: serial@40007c00 {
			compatible = "st,stm32-uart";      /* in zephyr\dts\arm\st\f4\stm32f427.dtsi:45 */
			reg = < 0x40007c00 0x400 >;        /* in zephyr\dts\arm\st\f4\stm32f427.dtsi:46 */
			clocks = < &rcc 0x40 0x80000000 >; /* in zephyr\dts\arm\st\f4\stm32f427.dtsi:47 */
			resets = < &rctl 0x41f >;          /* in zephyr\dts\arm\st\f4\stm32f427.dtsi:48 */
			interrupts = < 0x53 0x0 >;         /* in zephyr\dts\arm\st\f4\stm32f427.dtsi:49 */
			status = "disabled";               /* in zephyr\dts\arm\st\f4\stm32f427.dtsi:50 */
		};

		/* node '/soc/spi@40015000' defined in zephyr\dts\arm\st\f4\stm32f427.dtsi:66 */
		spi5: spi@40015000 {
			compatible = "st,stm32-spi";     /* in zephyr\dts\arm\st\f4\stm32f427.dtsi:67 */
			#address-cells = < 0x1 >;        /* in zephyr\dts\arm\st\f4\stm32f427.dtsi:68 */
			#size-cells = < 0x0 >;           /* in zephyr\dts\arm\st\f4\stm32f427.dtsi:69 */
			reg = < 0x40015000 0x400 >;      /* in zephyr\dts\arm\st\f4\stm32f427.dtsi:70 */
			clocks = < &rcc 0x44 0x100000 >; /* in zephyr\dts\arm\st\f4\stm32f427.dtsi:71 */
			interrupts = < 0x55 0x5 >;       /* in zephyr\dts\arm\st\f4\stm32f427.dtsi:72 */
			status = "disabled";             /* in zephyr\dts\arm\st\f4\stm32f427.dtsi:73 */
		};

		/* node '/soc/spi@40015400' defined in zephyr\dts\arm\st\f4\stm32f427.dtsi:79 */
		spi6: spi@40015400 {
			compatible = "st,stm32-spi";     /* in zephyr\dts\arm\st\f4\stm32f427.dtsi:80 */
			#address-cells = < 0x1 >;        /* in zephyr\dts\arm\st\f4\stm32f427.dtsi:81 */
			#size-cells = < 0x0 >;           /* in zephyr\dts\arm\st\f4\stm32f427.dtsi:82 */
			reg = < 0x40015400 0x400 >;      /* in zephyr\dts\arm\st\f4\stm32f427.dtsi:83 */
			clocks = < &rcc 0x44 0x200000 >; /* in zephyr\dts\arm\st\f4\stm32f427.dtsi:84 */
			interrupts = < 0x56 0x5 >;       /* in zephyr\dts\arm\st\f4\stm32f427.dtsi:85 */
			status = "disabled";             /* in zephyr\dts\arm\st\f4\stm32f427.dtsi:86 */
		};

		/* node '/soc/memory-controller@a0000000' defined in zephyr\dts\arm\st\f4\stm32f427.dtsi:89 */
		fmc: memory-controller@a0000000 {
			compatible = "st,stm32-fmc"; /* in zephyr\dts\arm\st\f4\stm32f427.dtsi:90 */
			reg = < 0xa0000000 0x400 >;  /* in zephyr\dts\arm\st\f4\stm32f427.dtsi:91 */
			clocks = < &rcc 0x38 0x1 >;  /* in zephyr\dts\arm\st\f4\stm32f427.dtsi:92 */
			status = "disabled";         /* in zephyr\dts\arm\st\f4\stm32f427.dtsi:93 */

			/* node '/soc/memory-controller@a0000000/sdram' defined in zephyr\dts\arm\st\f4\stm32f427.dtsi:95 */
			sdram: sdram {
				compatible = "st,stm32-fmc-sdram"; /* in zephyr\dts\arm\st\f4\stm32f427.dtsi:96 */
				#address-cells = < 0x1 >;          /* in zephyr\dts\arm\st\f4\stm32f427.dtsi:97 */
				#size-cells = < 0x0 >;             /* in zephyr\dts\arm\st\f4\stm32f427.dtsi:98 */
				status = "disabled";               /* in zephyr\dts\arm\st\f4\stm32f427.dtsi:99 */
			};
		};

		/* node '/soc/display-controller@40016800' defined in zephyr\dts\arm\st\f4\stm32f429.dtsi:22 */
		ltdc: display-controller@40016800 {
			compatible = "st,stm32-ltdc";     /* in zephyr\dts\arm\st\f4\stm32f429.dtsi:23 */
			reg = < 0x40016800 0x200 >;       /* in zephyr\dts\arm\st\f4\stm32f429.dtsi:24 */
			interrupts = < 0x58 0x0 >,
			             < 0x59 0x0 >;        /* in zephyr\dts\arm\st\f4\stm32f429.dtsi:25 */
			interrupt-names = "ltdc",
			                  "ltdc_er";      /* in zephyr\dts\arm\st\f4\stm32f429.dtsi:26 */
			clocks = < &rcc 0x44 0x4000000 >; /* in zephyr\dts\arm\st\f4\stm32f429.dtsi:27 */
			resets = < &rctl 0x49a >;         /* in zephyr\dts\arm\st\f4\stm32f429.dtsi:28 */
			status = "disabled";              /* in zephyr\dts\arm\st\f4\stm32f429.dtsi:29 */
		};
	};

	/* node '/cpus' defined in zephyr\dts\arm\st\f4\stm32f4.dtsi:30 */
	cpus {
		#address-cells = < 0x1 >; /* in zephyr\dts\arm\st\f4\stm32f4.dtsi:31 */
		#size-cells = < 0x0 >;    /* in zephyr\dts\arm\st\f4\stm32f4.dtsi:32 */

		/* node '/cpus/cpu@0' defined in zephyr\dts\arm\st\f4\stm32f4.dtsi:34 */
		cpu0: cpu@0 {
			device_type = "cpu";           /* in zephyr\dts\arm\st\f4\stm32f4.dtsi:35 */
			compatible = "arm,cortex-m4f"; /* in zephyr\dts\arm\st\f4\stm32f4.dtsi:36 */
			reg = < 0x0 >;                 /* in zephyr\dts\arm\st\f4\stm32f4.dtsi:37 */
			cpu-power-states = < &stop >;  /* in zephyr\dts\arm\st\f4\stm32f4.dtsi:38 */
		};

		/* node '/cpus/power-states' defined in zephyr\dts\arm\st\f4\stm32f4.dtsi:41 */
		power-states {

			/* node '/cpus/power-states/stop' defined in zephyr\dts\arm\st\f4\stm32f4.dtsi:42 */
			stop: stop {
				compatible = "zephyr,power-state";    /* in zephyr\dts\arm\st\f4\stm32f4.dtsi:43 */
				power-state-name = "suspend-to-idle"; /* in zephyr\dts\arm\st\f4\stm32f4.dtsi:44 */
				min-residency-us = < 0x190 >;         /* in zephyr\dts\arm\st\f4\stm32f4.dtsi:51 */
				exit-latency-us = < 0x12c >;          /* in zephyr\dts\arm\st\f4\stm32f4.dtsi:52 */
				phandle = < 0x1b >;                   /* in zephyr\dts\arm\st\f4\stm32f4.dtsi:38 */
			};
		};
	};

	/* node '/memory@20000000' defined in zephyr\dts\arm\st\f4\stm32f4.dtsi:57 */
	sram0: memory@20000000 {
		compatible = "mmio-sram";     /* in zephyr\dts\arm\st\f4\stm32f4.dtsi:58 */
		reg = < 0x20000000 0x50000 >; /* in zephyr\dts\arm\st\f4\stm32f469Xi.dtsi:18 */
	};

	/* node '/clocks' defined in zephyr\dts\arm\st\f4\stm32f4.dtsi:61 */
	clocks {

		/* node '/clocks/clk-hse' defined in zephyr\dts\arm\st\f4\stm32f4.dtsi:62 */
		clk_hse: clk-hse {
			#clock-cells = < 0x0 >;            /* in zephyr\dts\arm\st\f4\stm32f4.dtsi:63 */
			compatible = "st,stm32-hse-clock"; /* in zephyr\dts\arm\st\f4\stm32f4.dtsi:64 */
			clock-frequency = < 0x7a1200 >;    /* in zephyr\boards\st\stm32f469i_disco\stm32f469i_disco.dts:73 */
			status = "okay";                   /* in zephyr\boards\st\stm32f469i_disco\stm32f469i_disco.dts:74 */
			phandle = < 0x1c >;                /* in zephyr\boards\st\stm32f469i_disco\stm32f469i_disco.dts:82 */
		};

		/* node '/clocks/clk-hsi' defined in zephyr\dts\arm\st\f4\stm32f4.dtsi:68 */
		clk_hsi: clk-hsi {
			#clock-cells = < 0x0 >;         /* in zephyr\dts\arm\st\f4\stm32f4.dtsi:69 */
			compatible = "fixed-clock";     /* in zephyr\dts\arm\st\f4\stm32f4.dtsi:70 */
			clock-frequency = < 0xf42400 >; /* in zephyr\dts\arm\st\f4\stm32f4.dtsi:71 */
			status = "disabled";            /* in zephyr\dts\arm\st\f4\stm32f4.dtsi:72 */
		};

		/* node '/clocks/clk-lse' defined in zephyr\dts\arm\st\f4\stm32f4.dtsi:75 */
		clk_lse: clk-lse {
			#clock-cells = < 0x0 >;       /* in zephyr\dts\arm\st\f4\stm32f4.dtsi:76 */
			compatible = "fixed-clock";   /* in zephyr\dts\arm\st\f4\stm32f4.dtsi:77 */
			clock-frequency = < 0x8000 >; /* in zephyr\dts\arm\st\f4\stm32f4.dtsi:78 */
			status = "disabled";          /* in zephyr\dts\arm\st\f4\stm32f4.dtsi:79 */
		};

		/* node '/clocks/clk-lsi' defined in zephyr\dts\arm\st\f4\stm32f4.dtsi:82 */
		clk_lsi: clk-lsi {
			#clock-cells = < 0x0 >;       /* in zephyr\dts\arm\st\f4\stm32f4.dtsi:83 */
			compatible = "fixed-clock";   /* in zephyr\dts\arm\st\f4\stm32f4.dtsi:84 */
			clock-frequency = < 0x7d00 >; /* in zephyr\dts\arm\st\f4\stm32f4.dtsi:85 */
			status = "okay";              /* in zephyr\boards\st\stm32f469i_disco\stm32f469i_disco.dts:69 */
		};

		/* node '/clocks/pll' defined in zephyr\dts\arm\st\f4\stm32f4.dtsi:89 */
		pll: pll {
			#clock-cells = < 0x0 >;              /* in zephyr\dts\arm\st\f4\stm32f4.dtsi:90 */
			compatible = "st,stm32f4-pll-clock"; /* in zephyr\dts\arm\st\f4\stm32f4.dtsi:91 */
			div-m = < 0x8 >;                     /* in zephyr\boards\st\stm32f469i_disco\stm32f469i_disco.dts:78 */
			mul-n = < 0x150 >;                   /* in zephyr\boards\st\stm32f469i_disco\stm32f469i_disco.dts:79 */
			div-p = < 0x2 >;                     /* in zephyr\boards\st\stm32f469i_disco\stm32f469i_disco.dts:80 */
			div-q = < 0x7 >;                     /* in zephyr\boards\st\stm32f469i_disco\stm32f469i_disco.dts:81 */
			clocks = < &clk_hse >;               /* in zephyr\boards\st\stm32f469i_disco\stm32f469i_disco.dts:82 */
			status = "okay";                     /* in zephyr\boards\st\stm32f469i_disco\stm32f469i_disco.dts:83 */
			phandle = < 0x2 >;                   /* in zephyr\boards\st\stm32f469i_disco\stm32f469i_disco.dts:87 */
		};

		/* node '/clocks/plli2s' defined in zephyr\dts\arm\st\f4\stm32f401.dtsi:11 */
		plli2s: plli2s {
			#clock-cells = < 0x0 >;                 /* in zephyr\dts\arm\st\f4\stm32f401.dtsi:12 */
			compatible = "st,stm32f4-plli2s-clock"; /* in zephyr\dts\arm\st\f4\stm32f401.dtsi:13 */
			status = "disabled";                    /* in zephyr\dts\arm\st\f4\stm32f401.dtsi:14 */
		};
	};

	/* node '/mcos' defined in zephyr\dts\arm\st\f4\stm32f4.dtsi:96 */
	mcos {

		/* node '/mcos/mco1' defined in zephyr\dts\arm\st\f4\stm32f4.dtsi:97 */
		mco1: mco1 {
			compatible = "st,stm32-clock-mco"; /* in zephyr\dts\arm\st\f4\stm32f4.dtsi:98 */
			status = "disabled";               /* in zephyr\dts\arm\st\f4\stm32f4.dtsi:99 */
		};

		/* node '/mcos/mco2' defined in zephyr\dts\arm\st\f4\stm32f4.dtsi:102 */
		mco2: mco2 {
			compatible = "st,stm32-clock-mco"; /* in zephyr\dts\arm\st\f4\stm32f4.dtsi:103 */
			status = "disabled";               /* in zephyr\dts\arm\st\f4\stm32f4.dtsi:104 */
		};
	};

	/* node '/power@40007000' defined in zephyr\dts\arm\st\f4\stm32f4.dtsi:591 */
	pwr: power@40007000 {
		compatible = "st,stm32-pwr"; /* in zephyr\dts\arm\st\f4\stm32f4.dtsi:592 */
		reg = < 0x40007000 0x400 >;  /* in zephyr\dts\arm\st\f4\stm32f4.dtsi:593 */
		status = "disabled";         /* in zephyr\dts\arm\st\f4\stm32f4.dtsi:594 */
		wkup-pins-nb = < 0x1 >;      /* in zephyr\dts\arm\st\f4\stm32f4.dtsi:596 */
		#address-cells = < 0x1 >;    /* in zephyr\dts\arm\st\f4\stm32f4.dtsi:598 */
		#size-cells = < 0x0 >;       /* in zephyr\dts\arm\st\f4\stm32f4.dtsi:599 */

		/* node '/power@40007000/wkup-pin@1' defined in zephyr\dts\arm\st\f4\stm32f4.dtsi:601 */
		wkup-pin@1 {
			reg = < 0x1 >;                   /* in zephyr\dts\arm\st\f4\stm32f4.dtsi:602 */
			wkup-gpios = < &gpioa 0x0 0x1 >; /* in zephyr\dts\arm\st\f4\stm32f4.dtsi:603 */
		};
	};

	/* node '/dietemp' defined in zephyr\dts\arm\st\f4\stm32f4.dtsi:607 */
	die_temp: dietemp {
		compatible = "st,stm32-temp-cal"; /* in zephyr\dts\arm\st\f4\stm32f4.dtsi:608 */
		ts-cal1-addr = < 0x1fff7a2c >;    /* in zephyr\dts\arm\st\f4\stm32f4.dtsi:609 */
		ts-cal2-addr = < 0x1fff7a2e >;    /* in zephyr\dts\arm\st\f4\stm32f4.dtsi:610 */
		ts-cal1-temp = < 0x1e >;          /* in zephyr\dts\arm\st\f4\stm32f4.dtsi:611 */
		ts-cal2-temp = < 0x6e >;          /* in zephyr\dts\arm\st\f4\stm32f4.dtsi:612 */
		ts-cal-vrefanalog = < 0xce4 >;    /* in zephyr\dts\arm\st\f4\stm32f4.dtsi:613 */
		status = "disabled";              /* in zephyr\dts\arm\st\f4\stm32f4.dtsi:615 */
		io-channels = < &adc1 0x12 >;     /* in zephyr\dts\arm\st\f4\stm32f427.dtsi:105 */
	};

	/* node '/vref' defined in zephyr\dts\arm\st\f4\stm32f4.dtsi:618 */
	vref: vref {
		compatible = "st,stm32-vref";      /* in zephyr\dts\arm\st\f4\stm32f4.dtsi:619 */
		vrefint-cal-addr = < 0x1fff7a2a >; /* in zephyr\dts\arm\st\f4\stm32f4.dtsi:620 */
		vrefint-cal-mv = < 0xce4 >;        /* in zephyr\dts\arm\st\f4\stm32f4.dtsi:621 */
		io-channels = < &adc1 0x11 >;      /* in zephyr\dts\arm\st\f4\stm32f4.dtsi:622 */
		status = "disabled";               /* in zephyr\dts\arm\st\f4\stm32f4.dtsi:623 */
	};

	/* node '/vbat' defined in zephyr\dts\arm\st\f4\stm32f4.dtsi:626 */
	vbat: vbat {
		compatible = "st,stm32-vbat"; /* in zephyr\dts\arm\st\f4\stm32f4.dtsi:627 */
		ratio = < 0x4 >;              /* in zephyr\dts\arm\st\f4\stm32f4.dtsi:628 */
		io-channels = < &adc1 0x12 >; /* in zephyr\dts\arm\st\f4\stm32f4.dtsi:629 */
		status = "disabled";          /* in zephyr\dts\arm\st\f4\stm32f4.dtsi:630 */
	};

	/* node '/otgfs_phy' defined in zephyr\dts\arm\st\f4\stm32f4.dtsi:633 */
	otgfs_phy: otgfs_phy {
		compatible = "usb-nop-xceiv"; /* in zephyr\dts\arm\st\f4\stm32f4.dtsi:634 */
		#phy-cells = < 0x0 >;         /* in zephyr\dts\arm\st\f4\stm32f4.dtsi:635 */
		phandle = < 0x9 >;            /* in zephyr\dts\arm\st\f4\stm32f4.dtsi:320 */
	};

	/* node '/smbus1' defined in zephyr\dts\arm\st\f4\stm32f4.dtsi:638 */
	smbus1: smbus1 {
		compatible = "st,stm32-smbus"; /* in zephyr\dts\arm\st\f4\stm32f4.dtsi:639 */
		#address-cells = < 0x1 >;      /* in zephyr\dts\arm\st\f4\stm32f4.dtsi:640 */
		#size-cells = < 0x0 >;         /* in zephyr\dts\arm\st\f4\stm32f4.dtsi:641 */
		i2c = < &i2c1 >;               /* in zephyr\dts\arm\st\f4\stm32f4.dtsi:642 */
		status = "disabled";           /* in zephyr\dts\arm\st\f4\stm32f4.dtsi:643 */
	};

	/* node '/smbus2' defined in zephyr\dts\arm\st\f4\stm32f4.dtsi:646 */
	smbus2: smbus2 {
		compatible = "st,stm32-smbus"; /* in zephyr\dts\arm\st\f4\stm32f4.dtsi:647 */
		#address-cells = < 0x1 >;      /* in zephyr\dts\arm\st\f4\stm32f4.dtsi:648 */
		#size-cells = < 0x0 >;         /* in zephyr\dts\arm\st\f4\stm32f4.dtsi:649 */
		i2c = < &i2c2 >;               /* in zephyr\dts\arm\st\f4\stm32f4.dtsi:650 */
		status = "disabled";           /* in zephyr\dts\arm\st\f4\stm32f4.dtsi:651 */
	};

	/* node '/smbus3' defined in zephyr\dts\arm\st\f4\stm32f4.dtsi:654 */
	smbus3: smbus3 {
		compatible = "st,stm32-smbus"; /* in zephyr\dts\arm\st\f4\stm32f4.dtsi:655 */
		#address-cells = < 0x1 >;      /* in zephyr\dts\arm\st\f4\stm32f4.dtsi:656 */
		#size-cells = < 0x0 >;         /* in zephyr\dts\arm\st\f4\stm32f4.dtsi:657 */
		i2c = < &i2c3 >;               /* in zephyr\dts\arm\st\f4\stm32f4.dtsi:658 */
		status = "disabled";           /* in zephyr\dts\arm\st\f4\stm32f4.dtsi:659 */
	};

	/* node '/otghs_fs_phy' defined in zephyr\dts\arm\st\f4\stm32f405.dtsi:287 */
	otghs_fs_phy: otghs_fs_phy {
		compatible = "usb-nop-xceiv"; /* in zephyr\dts\arm\st\f4\stm32f405.dtsi:288 */
		#phy-cells = < 0x0 >;         /* in zephyr\dts\arm\st\f4\stm32f405.dtsi:289 */
		phandle = < 0x1a >;           /* in zephyr\dts\arm\st\f4\stm32f405.dtsi:202 */
	};

	/* node '/memory@10000000' defined in zephyr\dts\arm\st\f4\stm32f469Xi.dtsi:11 */
	ccm0: memory@10000000 {
		compatible = "zephyr,memory-region",
		             "st,stm32-ccm";         /* in zephyr\dts\arm\st\f4\stm32f469Xi.dtsi:12 */
		reg = < 0x10000000 0x10000 >;        /* in zephyr\dts\arm\st\f4\stm32f469Xi.dtsi:13 */
		zephyr,memory-region = "CCM";        /* in zephyr\dts\arm\st\f4\stm32f469Xi.dtsi:14 */
	};

	/* node '/connector' defined in zephyr\boards\st\stm32f469i_disco\arduino_r3_connector.dtsi:8 */
	arduino_header: connector {
		compatible = "arduino-header-r3";          /* in zephyr\boards\st\stm32f469i_disco\arduino_r3_connector.dtsi:9 */
		#gpio-cells = < 0x2 >;                     /* in zephyr\boards\st\stm32f469i_disco\arduino_r3_connector.dtsi:10 */
		gpio-map-mask = < 0xffffffff 0xffffffc0 >; /* in zephyr\boards\st\stm32f469i_disco\arduino_r3_connector.dtsi:11 */
		gpio-map-pass-thru = < 0x0 0x3f >;         /* in zephyr\boards\st\stm32f469i_disco\arduino_r3_connector.dtsi:12 */
		gpio-map = < 0x0 0x0 &gpiob 0x1 0x0 >,
		           < 0x1 0x0 &gpioc 0x2 0x0 >,
		           < 0x2 0x0 &gpioc 0x3 0x0 >,
		           < 0x3 0x0 &gpioc 0x4 0x0 >,
		           < 0x4 0x0 &gpioc 0x5 0x0 >,
		           < 0x5 0x0 &gpioa 0x4 0x0 >,
		           < 0x6 0x0 &gpiog 0x9 0x0 >,
		           < 0x7 0x0 &gpiog 0xe 0x0 >,
		           < 0x8 0x0 &gpiog 0xf 0x0 >,
		           < 0x9 0x0 &gpioa 0x1 0x0 >,
		           < 0xa 0x0 &gpiog 0xc 0x0 >,
		           < 0xb 0x0 &gpioa 0x2 0x0 >,
		           < 0xc 0x0 &gpioa 0x6 0x0 >,
		           < 0xd 0x0 &gpiog 0xb 0x0 >,
		           < 0xe 0x0 &gpiog 0xa 0x0 >,
		           < 0xf 0x0 &gpioa 0x7 0x0 >,
		           < 0x10 0x0 &gpioh 0x6 0x0 >,
		           < 0x11 0x0 &gpiob 0xf 0x0 >,
		           < 0x12 0x0 &gpiob 0xe 0x0 >,
		           < 0x13 0x0 &gpiod 0x3 0x0 >,
		           < 0x14 0x0 &gpiob 0x9 0x0 >,
		           < 0x15 0x0 &gpiob 0x8 0x0 >;    /* in zephyr\boards\st\stm32f469i_disco\arduino_r3_connector.dtsi:13 */
	};

	/* node '/leds' defined in zephyr\boards\st\stm32f469i_disco\stm32f469i_disco.dts:25 */
	leds {
		compatible = "gpio-leds"; /* in zephyr\boards\st\stm32f469i_disco\stm32f469i_disco.dts:26 */

		/* node '/leds/led_1' defined in zephyr\boards\st\stm32f469i_disco\stm32f469i_disco.dts:28 */
		green_led_1: led_1 {
			gpios = < &gpiog 0x6 0x0 >; /* in zephyr\boards\st\stm32f469i_disco\stm32f469i_disco.dts:29 */
			label = "User LD1";         /* in zephyr\boards\st\stm32f469i_disco\stm32f469i_disco.dts:30 */
		};

		/* node '/leds/led_2' defined in zephyr\boards\st\stm32f469i_disco\stm32f469i_disco.dts:33 */
		orange_led_2: led_2 {
			gpios = < &gpiod 0x4 0x0 >; /* in zephyr\boards\st\stm32f469i_disco\stm32f469i_disco.dts:34 */
			label = "User LD2";         /* in zephyr\boards\st\stm32f469i_disco\stm32f469i_disco.dts:35 */
		};

		/* node '/leds/led_3' defined in zephyr\boards\st\stm32f469i_disco\stm32f469i_disco.dts:38 */
		red_led_3: led_3 {
			gpios = < &gpiod 0x5 0x0 >; /* in zephyr\boards\st\stm32f469i_disco\stm32f469i_disco.dts:39 */
			label = "User LD3";         /* in zephyr\boards\st\stm32f469i_disco\stm32f469i_disco.dts:40 */
		};

		/* node '/leds/led_4' defined in zephyr\boards\st\stm32f469i_disco\stm32f469i_disco.dts:43 */
		blue_led_4: led_4 {
			gpios = < &gpiok 0x3 0x0 >; /* in zephyr\boards\st\stm32f469i_disco\stm32f469i_disco.dts:44 */
			label = "User LD4";         /* in zephyr\boards\st\stm32f469i_disco\stm32f469i_disco.dts:45 */
		};
	};

	/* node '/gpio_keys' defined in zephyr\boards\st\stm32f469i_disco\stm32f469i_disco.dts:49 */
	gpio_keys {
		compatible = "gpio-keys"; /* in zephyr\boards\st\stm32f469i_disco\stm32f469i_disco.dts:50 */

		/* node '/gpio_keys/button' defined in zephyr\boards\st\stm32f469i_disco\stm32f469i_disco.dts:52 */
		user_button: button {
			label = "User";             /* in zephyr\boards\st\stm32f469i_disco\stm32f469i_disco.dts:53 */
			gpios = < &gpioa 0x0 0x1 >; /* in zephyr\boards\st\stm32f469i_disco\stm32f469i_disco.dts:54 */
			zephyr,code = < 0xb >;      /* in zephyr\boards\st\stm32f469i_disco\stm32f469i_disco.dts:55 */
		};
	};
};
